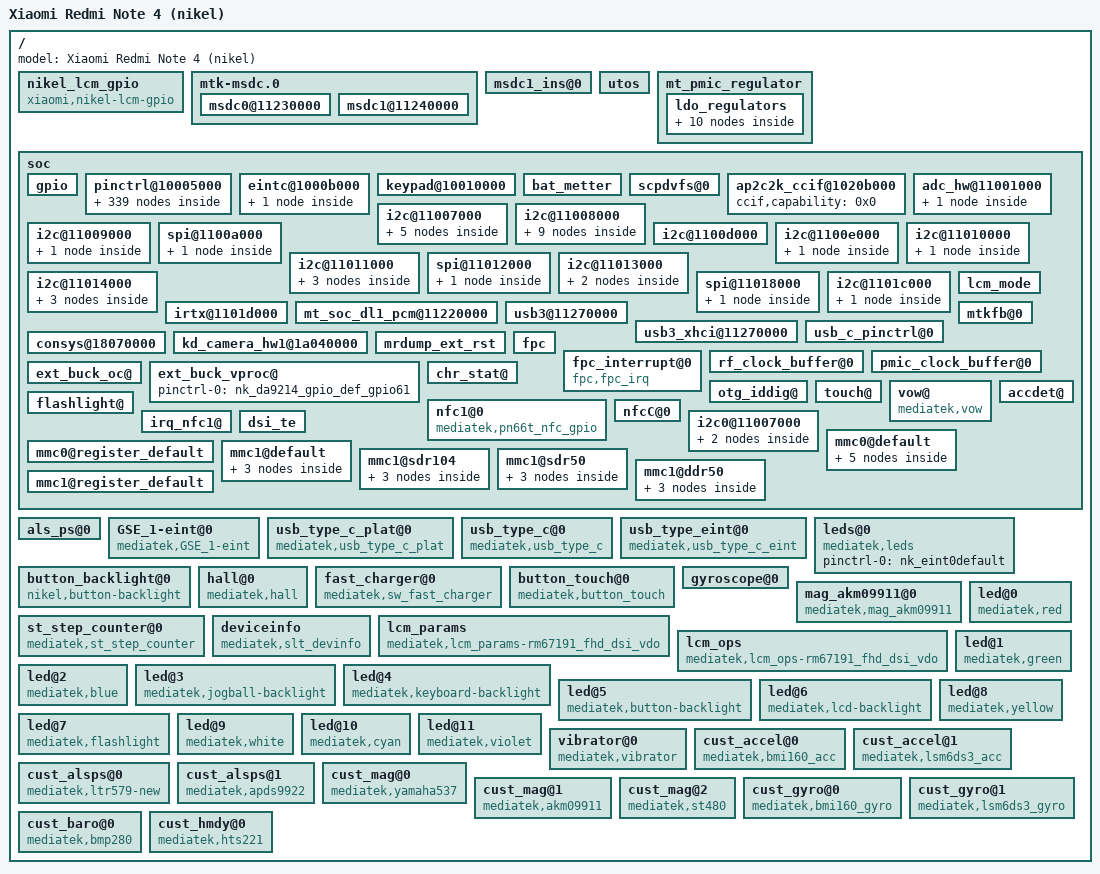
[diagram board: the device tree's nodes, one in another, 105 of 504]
/*
 * Redmi Note 4 (MTK, "nikel") - board device tree
 * Target: SHIFTPHONES/android_kernel_shift_mt6797 (shift-8.0-mtk, 3.18.60)
 * Built as CONFIG_BUILD_ARM64_APPENDED_DTB_IMAGE_NAMES="nikel" (nikel_defconfig),
 * one merged DTB appended to the kernel, no odmdtbo (nikel's LK has none).
 *
 * GENERATED DRAFT. Built by diffing nikel's stock DTB (Xiaomi kernel
 * 3.18.M2+, 2019-04-19, taken from a LineageOS 14.1 boot.img) against the
 * SoC tree inside SHIFT5ME.SOS.2.0.L.20230421's boot.img. Only what nikel's
 * board needs on top of SHIFT's mt6797.dtsi is here.
 *
 * Rules used:
 *  - Board data (pins, I2C/SPI devices, EINTs, touch, keypad, LEDs, sensors,
 *    camera power, LCM pins, battery tables) = nikel stock, verbatim.
 *  - SoC/kernel-version data (clock IDs, driver compatibles, I2C PM flags)
 *    = SHIFT, untouched.
 *  - Firmware-tied data (TEE interrupts, modem CCIF) = nikel, because nikel
 *    keeps its own TEE and modem images.
 *  - Phandles rewritten: SHIFT labels where they exist, otherwise generated
 *    "nk_*" labels on nikel's own pin-state nodes.
 *
 * Not yet compiled. First test: build with the kernel's dtc, then compare the
 * result against nikel's stock DTB with the same diff script.
 */

/dts-v1/;

/*
 * SHIFT's MT6797 SoC description - the same file SHIFT5me.dts includes when
 * CONFIG_MTK_DTBO_FEATURE is off, and the source of the base DTB this board
 * file was diffed against.
 */
#include "SHIFT5me_mt6797.dts"

/ {
	model = "Xiaomi Redmi Note 4 (nikel)";

	/*
	 * SHIFT5me_mt6797.dts declares early-mount entries here for system
	 * (non-A/B, with verity), vendor and optionally odm. nikel has no vendor
	 * or odm partition and mounts system from its normal fstab: without this
	 * deletion Android 8 init tries the early mounts and stops.
	 */
	/delete-node/ firmware;

	/*
	 * Panel pins for the nt35596_fhd_tianma_phantom driver, which drives
	 * reset, bias and backlight-enable itself (SHIFT's display driver only
	 * offers register-based reset and a combined bias switch).
	 * RST GPIO180, ENP GPIO87, ENN GPIO108, BL_EN GPIO50 - nikel stock states.
	 */
	nikel_lcm_gpio {
		compatible = "xiaomi,nikel-lcm-gpio";
		pinctrl-names = "rst0", "rst1", "enp0", "enp1", "enn0", "enn1", "bl0", "bl1";
		pinctrl-0 = <&nk_lcm_rst_out0_gpio>;
		pinctrl-1 = <&nk_lcm_rst_out1_gpio>;
		pinctrl-2 = <&nk_lcd_bias_enp_gpio_low>;
		pinctrl-3 = <&nk_lcd_bias_enp_gpio_high>;
		pinctrl-4 = <&nk_lcd_bias_enn_gpio_low>;
		pinctrl-5 = <&nk_lcd_bias_enn_gpio_high>;
		pinctrl-6 = <&nk_lcd_backlight_en_gpio_low>;
		pinctrl-7 = <&nk_lcd_backlight_en_gpio_high>;
		status = "okay";
	};
	mtk-msdc.0 {
		msdc0@11230000 {
			status = "okay";
			clk_src = [01];
			bus-width = <0x8>;
			max-frequency = <0xbebc200>;
			cap-mmc-highspeed;
			msdc-sys-suspend;
			mmc-ddr-1_8v;
			mmc-hs200-1_8v;
			mmc-hs400-1_8v;
			non-removable;
			pinctl = <0x3>;
			register_setting = <0x4>;
			host_function = [00];
			bootable;
		};
		msdc1@11240000 {
			status = "okay";
			clk_src = [02];
			bus-width = <0x4>;
			max-frequency = <0xbebc200>;
			msdc-sys-suspend;
			cap-sd-highspeed;
			sd-uhs-sdr12;
			sd-uhs-sdr25;
			sd-uhs-sdr50;
			sd-uhs-sdr104;
			pinctl = <0x5>;
			pinctl_sdr104 = <0x6>;
			pinctl_sdr50 = <0x7>;
			pinctl_ddr50 = <0x8>;
			register_setting = <0x9>;
			host_function = [01];
			cd_level = [00];
			cd-gpios = <&pio 0x43 0x0>;
		};
	};
	msdc1_ins@0 {
		interrupt-parent = <&eintc>;
		interrupts = <0x43 0x8>;
		debounce = <0x43 0x3e8>;
		status = "okay";
	};
	utos {
		interrupts = <0x0 0x126 0x1 0x0 0x127 0x1 0x0 0x128 0x1 0x0 0x12c 0x1
			    0x0 0x12d 0x1 0x0 0x12e 0x1 0x0 0x12f 0x1 0x0 0x131 0x1>;
	};
	mt_pmic_regulator {
		ldo_regulators {
			ldo_vcama {
				regulator-default-on = <0x1>;
				status = "okay";
			};
			ldo_vsim1 {
				regulator-default-on = <0x1>;
				status = "okay";
			};
			ldo_vsim2 {
				regulator-default-on = <0x1>;
				status = "okay";
			};
			ldo_vmch {
				regulator-boot-on;
			};
			ldo_vibr {
				regulator-default-on = <0x1>;
				status = "okay";
			};
			ldo_vcamd {
				regulator-default-on = <0x1>;
				status = "okay";
			};
			ldo_vcamio {
				regulator-default-on = <0x1>;
				status = "okay";
			};
			ldo_vgp3 {
				regulator-default-on = <0x1>;
				status = "okay";
			};
			ldo_vldo28 {
				regulator-default-on = <0x1>;
				status = "okay";
			};
			ldo_vmc {
				regulator-boot-on;
			};
		};
	};
	soc {
		gpio {
			GPIO_SIM1_HOT_PLUG = <0x70>;
			GPIO_SIM2_HOT_PLUG = <0x71>;
			GPIO_SIM1_SCLK = <0x7e>;
			GPIO_SIM1_SRST = <0x7f>;
			GPIO_SIM1_SIO = <0x80>;
			GPIO_SIM2_SCLK = <0x9b>;
			GPIO_SIM2_SRST = <0x9c>;
			GPIO_SIM2_SIO = <0x9d>;
		};
		pinctrl@10005000 {
			nk_default: default {
			};
			nk_bq_dsel_en_l: bq_dsel_en_l {
				pins_cmd_dat {
					pins = <0x8a00>;
					slew-rate = <0x1>;
					output-low;
				};
			};
			nk_bq_dsel_en_h: bq_dsel_en_h {
				pins_cmd_dat {
					pins = <0x8a00>;
					slew-rate = <0x1>;
					output-high;
				};
			};
			nk_alspspincfg: alspspincfg {
				pins_cmd_dat {
					pins = <0x5801>;
					slew-rate = <0x0>;
					bias-pull-up = <0x0>;
				};
			};
			nk_alspsdefaultcfg: alspsdefaultcfg {
			};
			nk_steppincfg: steppincfg {
				pins_cmd_dat {
					pins = <0x3e01>;
					slew-rate = <0x0>;
					bias-pull-up = <0x0>;
				};
			};
			nk_stepdefaultcfg: stepdefaultcfg {
			};
			nk_gyropincfg: gyropincfg {
				pins_cmd_dat {
					pins = <0x3f00>;
					slew-rate = <0x0>;
					bias-pull-down = <0x0>;
				};
			};
			nk_gyrodefaultcfg: gyrodefaultcfg {
			};
			nk_magpincfg: magpincfg {
				pins_cmd_dat {
					pins = <0x4000>;
					slew-rate = <0x1>;
					bias-disable;
					bias-pull-down = <0x0>;
					bias-pull-up = <0x0>;
					input-disable;
					input-schmitt-enable = <0x0>;
					output-high;
				};
			};
			nk_magdefaultcfg: magdefaultcfg {
				pins_cmd_dat {
					pins = <0x4000>;
					slew-rate = <0x1>;
					bias-disable;
					bias-pull-down = <0x0>;
					bias-pull-up = <0x0>;
					input-disable;
					input-schmitt-enable = <0x0>;
					output-low;
				};
			};
			nk_state_default: state_default {
			};
			nk_state_reset_high: state_reset_high {
				pins_cmd_dat {
					pins = <0x2b00>;
					slew-rate = <0x1>;
					output-high;
				};
			};
			nk_state_reset_low: state_reset_low {
				pins_cmd_dat {
					pins = <0x2b00>;
					slew-rate = <0x1>;
					output-low;
				};
			};
			nk_state_power_on: state_power_on {
				pins_cmd_dat {
					pins = <0x8b00>;
					slew-rate = <0x1>;
					output-high;
				};
			};
			nk_state_power_off: state_power_off {
				pins_cmd_dat {
					pins = <0x8b00>;
					slew-rate = <0x1>;
					output-low;
				};
			};
			nk_state_gf_irq: state_gf_irq {
				pins_cmd_dat {
					pins = <0x5601>;
					slew-rate = <0x0>;
					bias-disable;
				};
			};
			nk_state_tas_mod_switch1_high: state_tas_mod_switch1_high {
				pins_cmd_dat {
					pins = <0xc900>;
					slew-rate = <0x1>;
					bias-disable;
					output-high;
				};
			};
			nk_state_tas_mod_switch1_low: state_tas_mod_switch1_low {
				pins_cmd_dat {
					pins = <0xc900>;
					slew-rate = <0x1>;
					bias-disable;
					output-low;
				};
			};
			nk_state_tas_mod_switch2_high: state_tas_mod_switch2_high {
				pins_cmd_dat {
					pins = <0xcb00>;
					slew-rate = <0x1>;
					bias-disable;
					output-high;
				};
			};
			nk_state_tas_mod_switch2_low: state_tas_mod_switch2_low {
				pins_cmd_dat {
					pins = <0xcb00>;
					slew-rate = <0x1>;
					bias-disable;
					output-low;
				};
			};
			nk_state_tas_mod_switch1_bpi_mode: state_tas_mod_switch1_bpi_mode {
				pins_cmd_dat {
					pins = <0xc901>;
					slew-rate = <0x1>;
					bias-disable;
				};
			};
			nk_state_tas_mod_switch2_bpi_mode: state_tas_mod_switch2_bpi_mode {
				pins_cmd_dat {
					pins = <0xcb01>;
					slew-rate = <0x1>;
					bias-disable;
				};
			};
			nk_st1_eint_init: st1_eint_init {
				pins_cmd_dat {
					pins = <0x5d01>;
					slew-rate = <0x0>;
					bias-pull-down = <0x0>;
				};
			};
			nk_st1_se_eint_init: st1_se_eint_init {
				pins_cmd_dat {
					pins = <0x5901>;
					slew-rate = <0x0>;
					bias-pull-up = <0x0>;
				};
			};
			nk_st1_ven_high: st1_ven_high {
				pins_cmd_dat {
					pins = <0x3b00>;
					slew-rate = <0x1>;
					output-high;
				};
			};
			nk_st1_ven_low: st1_ven_low {
				pins_cmd_dat {
					pins = <0x3b00>;
					slew-rate = <0x1>;
					output-low;
				};
			};
			nk_st1_dl_req_high: st1_dl_req_high {
				pins_cmd_dat {
					pins = <0x2700>;
					slew-rate = <0x1>;
					output-high;
				};
			};
			nk_st1_dl_req_low: st1_dl_req_low {
				pins_cmd_dat {
					pins = <0x2700>;
					slew-rate = <0x1>;
					output-low;
				};
			};
			nk_st1_se_en_high: st1_se_en_high {
				pins_cmd_dat {
					pins = <0x2800>;
					slew-rate = <0x1>;
					output-high;
				};
			};
			nk_st1_se_en_low: st1_se_en_low {
				pins_cmd_dat {
					pins = <0x2800>;
					slew-rate = <0x1>;
					output-low;
				};
			};
			nk_st1_pvdd_en_high: st1_pvdd_en_high {
				pins_cmd_dat {
					pins = <0x2900>;
					slew-rate = <0x1>;
					output-high;
				};
			};
			nk_st1_pvdd_en_low: st1_pvdd_en_low {
				pins_cmd_dat {
					pins = <0x2900>;
					slew-rate = <0x1>;
					output-low;
				};
			};
			nk_st1_se_rst_high: st1_se_rst_high {
				pins_cmd_dat {
					pins = <0x2a00>;
					slew-rate = <0x1>;
					output-high;
				};
			};
			nk_st1_se_rst_low: st1_se_rst_low {
				pins_cmd_dat {
					pins = <0x2a00>;
					slew-rate = <0x1>;
					output-low;
				};
			};
			nk_state_ven_high: state_ven_high {
				pins_cmd_dat {
					pins = <0x3c00>;
					slew-rate = <0x1>;
					output-high;
				};
			};
			nk_state_ven_low: state_ven_low {
				pins_cmd_dat {
					pins = <0x3c00>;
					slew-rate = <0x1>;
					output-low;
				};
			};
			nk_state_rst_high: state_rst_high {
				pins_cmd_dat {
					pins = <0x3b00>;
					slew-rate = <0x1>;
					output-high;
				};
			};
			nk_state_rst_low: state_rst_low {
				pins_cmd_dat {
					pins = <0x3b00>;
					slew-rate = <0x1>;
					output-low;
				};
			};
			nk_state_eint_high: state_eint_high {
				pins_cmd_dat {
					pins = <0x3900>;
					slew-rate = <0x1>;
					output-high;
				};
			};
			nk_state_eint_low: state_eint_low {
				pins_cmd_dat {
					pins = <0x3900>;
					slew-rate = <0x1>;
					output-low;
				};
			};
			nk_state_irq_init: state_irq_init {
				pins_cmd_dat {
					pins = <0x1c00>;
					slew-rate = <0x0>;
					bias-pull-down = <0x0>;
				};
			};
			nk_state_osc_init: state_osc_init {
				pins_cmd_dat {
					pins = <0x6400>;
					slew-rate = <0x1>;
					bias-pull-down = <0x0>;
				};
			};
			nk_state_cs_low: state_cs_low {
				pins_cmd_dat {
					pins = <0xf500>;
					slew-rate = <0x1>;
					output-low;
					input-disable;
				};
			};
			nk_state_mo_low: state_mo_low {
				pins_cmd_dat {
					pins = <0xf400>;
					slew-rate = <0x1>;
					output-low;
					input-disable;
				};
			};
			nk_state_mi_low: state_mi_low {
				pins_cmd_dat {
					pins = <0xf300>;
					slew-rate = <0x1>;
					output-low;
					input-disable;
				};
			};
			nk_state_sck_low: state_sck_low {
				pins_cmd_dat {
					pins = <0xf200>;
					slew-rate = <0x1>;
					output-low;
					input-disable;
				};
			};
			nk_eint0default: eint0default {
			};
			nk_eint_0: eint@0 {
				pins_cmd_dat {
					pins = <0x5501>;
					slew-rate = <0x0>;
					bias-disable;
				};
			};
			nk_eintoutput0: eintoutput0 {
				pins_cmd_dat {
					pins = <0x5500>;
					slew-rate = <0x1>;
					output-low;
				};
			};
			nk_eintoutput1: eintoutput1 {
				pins_cmd_dat {
					pins = <0x5500>;
					slew-rate = <0x1>;
					output-high;
				};
			};
			nk_rstoutput0: rstoutput0 {
				pins_cmd_dat {
					pins = <0x4400>;
					slew-rate = <0x1>;
					output-low;
				};
			};
			nk_rstoutput1: rstoutput1 {
				pins_cmd_dat {
					pins = <0x4400>;
					slew-rate = <0x1>;
					output-high;
				};
			};
			nk_regulator_en_output0: regulator_en_output0 {
				pins_cmd_dat {
					pins = <0x3a00>;
					slew-rate = <0x1>;
					output-low;
				};
			};
			nk_regulator_en_output1: regulator_en_output1 {
				pins_cmd_dat {
					pins = <0x3a00>;
					slew-rate = <0x1>;
					output-high;
				};
			};
			nk_accdetdefault: accdetdefault {
			};
			nk_accdeteint_0: accdeteint@0 {
				pins_cmd_dat {
					pins = <0x5c01>;
					slew-rate = <0x0>;
					bias-disable;
				};
			};
			nk_aud_clk_mosi_off: aud_clk_mosi_off {
				pins_cmd0_dat {
					pins = <0x9200>;
				};
			};
			nk_aud_clk_mosi_on: aud_clk_mosi_on {
				pins_cmd0_dat {
					pins = <0x9201>;
				};
			};
			nk_aud_pins_smartpa_mode0: aud_pins_smartpa_mode0 {
				pins_cmd0_dat {
					pins = <0x4500>;
				};
				pins_cmd1_dat {
					pins = <0x4600>;
				};
				pins_cmd2_dat {
					pins = <0x4800>;
				};
				pins_cmd3_dat {
					pins = <0x4900>;
				};
			};
			nk_aud_pins_smartpa_mode1: aud_pins_smartpa_mode1 {
				pins_cmd0_dat {
					pins = <0x4501>;
				};
				pins_cmd1_dat {
					pins = <0x4601>;
				};
				pins_cmd2_dat {
					pins = <0x4802>;
				};
				pins_cmd3_dat {
					pins = <0x4902>;
				};
			};
			nk_aud_pins_smartpa_mode3: aud_pins_smartpa_mode3 {
				pins_cmd0_dat {
					pins = <0x4503>;
				};
				pins_cmd1_dat {
					pins = <0x4603>;
				};
				pins_cmd2_dat {
					pins = <0x4804>;
				};
				pins_cmd3_dat {
					pins = <0x4904>;
				};
			};
			nk_aud_pins_tdm_mode0: aud_pins_tdm_mode0 {
				pins_cmd0_dat {
					pins = <0x7100>;
				};
				pins_cmd1_dat {
					pins = <0x8800>;
				};
				pins_cmd2_dat {
					pins = <0x8a00>;
				};
			};
			nk_aud_pins_tdm_mode1: aud_pins_tdm_mode1 {
				pins_cmd0_dat {
					pins = <0x8701>;
				};
				pins_cmd1_dat {
					pins = <0x8801>;
				};
				pins_cmd2_dat {
					pins = <0x8a01>;
				};
			};
			nk_audhpdepophigh: audhpdepophigh {
				pins_cmd_dat {
					pins = <0x6f00>;
					slew-rate = <0x1>;
					output-high;
				};
			};
			nk_audhpdepoplow: audhpdepoplow {
				pins_cmd_dat {
					pins = <0x6f00>;
					slew-rate = <0x1>;
					output-low;
				};
			};
			nk_aud_dat_miso_off: aud_dat_miso_off {
				pins_cmd1_dat {
					pins = <0x9300>;
				};
			};
			nk_aud_dat_miso_on: aud_dat_miso_on {
				pins_cmd1_dat {
					pins = <0x9301>;
				};
			};
			nk_aud_dat_mosi_off: aud_dat_mosi_off {
				pins_cmd2_dat {
					pins = <0x9400>;
				};
			};
			nk_aud_dat_mosi_on: aud_dat_mosi_on {
				pins_cmd2_dat {
					pins = <0x9401>;
				};
			};
			nk_vow_dat_miso_off: vow_dat_miso_off {
				pins_cmd1_dat {
					pins = <0x9300>;
				};
			};
			nk_vow_dat_miso_on: vow_dat_miso_on {
				pins_cmd1_dat {
					pins = <0x9303>;
				};
			};
			nk_vow_clk_miso_off: vow_clk_miso_off {
				pins_cmd3_dat {
					pins = <0x9500>;
				};
			};
			nk_vow_clk_miso_on: vow_clk_miso_on {
				pins_cmd3_dat {
					pins = <0x9501>;
				};
			};
			nk_anc_dat_mosi_off: anc_dat_mosi_off {
				pins_cmd4_dat {
					pins = <0x9600>;
				};
			};
			nk_anc_dat_mosi_on: anc_dat_mosi_on {
				pins_cmd4_dat {
					pins = <0x9601>;
				};
			};
			nk_aud_extamp_high: aud_extamp_high {
				pins_cmd_dat {
					pins = <0x4700>;
					slew-rate = <0x1>;
					output-high;
				};
			};
			nk_aud_extamp_low: aud_extamp_low {
				pins_cmd_dat {
					pins = <0x4700>;
					slew-rate = <0x1>;
					output-low;
				};
			};
			nk_mode_te_gpio: mode_te_gpio {
				pins_cmd_dat {
					pins = <0xb301>;
				};
			};
			nk_mode_te_te: mode_te_te {
				pins_cmd_dat {
					pins = <0xb301>;
				};
			};
			nk_lcm_rst_out0_gpio: lcm_rst_out0_gpio {
				pins_cmd_dat {
					pins = <0xb400>;
					slew-rate = <0x1>;
					output-low;
				};
			};
			nk_lcm_rst_out1_gpio: lcm_rst_out1_gpio {
				pins_cmd_dat {
					pins = <0xb400>;
					slew-rate = <0x1>;
					output-high;
				};
			};
			nk_lcd_bias_enp_gpio_high: lcd_bias_enp_gpio_high {
				pins_cmd_dat {
					pins = <0x5700>;
					slew-rate = <0x1>;
					output-high;
				};
			};
			nk_lcd_bias_enp_gpio_low: lcd_bias_enp_gpio_low {
				pins_cmd_dat {
					pins = <0x5700>;
					slew-rate = <0x1>;
					output-low;
				};
			};
			nk_lcd_pwr_en_gpio_high: lcd_pwr_en_gpio_high {
				pins_cmd_dat {
					pins = <0x2d00>;
					slew-rate = <0x1>;
					output-high;
				};
			};
			nk_lcd_pwr_en_gpio_low: lcd_pwr_en_gpio_low {
				pins_cmd_dat {
					pins = <0x2d00>;
					slew-rate = <0x1>;
					output-low;
				};
			};
			nk_lcd_bias_enn_gpio_high: lcd_bias_enn_gpio_high {
				pins_cmd_dat {
					pins = <0x6c00>;
					slew-rate = <0x1>;
					output-high;
				};
			};
			nk_lcd_bias_enn_gpio_low: lcd_bias_enn_gpio_low {
				pins_cmd_dat {
					pins = <0x6c00>;
					slew-rate = <0x1>;
					output-low;
				};
			};
			nk_lcd_backlight_en_gpio_high: lcd_backlight_en_gpio_high {
				pins_cmd_dat {
					pins = <0x3200>;
					slew-rate = <0x1>;
					output-high;
				};
			};
			nk_lcd_backlight_en_gpio_low: lcd_backlight_en_gpio_low {
				pins_cmd_dat {
					pins = <0x3200>;
					slew-rate = <0x1>;
					output-low;
				};
			};
			nk_cam0_0: cam0@0 {
				pins_cmd_dat {
					pins = <0x2000>;
					slew-rate = <0x1>;
					output-low;
				};
			};
			nk_cam0_1: cam0@1 {
				pins_cmd_dat {
					pins = <0x2000>;
					slew-rate = <0x1>;
					output-high;
				};
			};
			nk_cam0_2: cam0@2 {
				pins_cmd_dat {
					pins = <0x1c00>;
					slew-rate = <0x1>;
					output-low;
				};
			};
			nk_cam0_3: cam0@3 {
				pins_cmd_dat {
					pins = <0x1c00>;
					slew-rate = <0x1>;
					output-high;
				};
			};
			nk_cam1_0: cam1@0 {
				pins_cmd_dat {
					pins = <0x2100>;
					slew-rate = <0x1>;
					output-low;
				};
			};
			nk_cam1_1: cam1@1 {
				pins_cmd_dat {
					pins = <0x2100>;
					slew-rate = <0x1>;
					output-high;
				};
			};
			nk_cam1_2: cam1@2 {
				pins_cmd_dat {
					pins = <0x1d00>;
					slew-rate = <0x1>;
					output-low;
				};
			};
			nk_cam1_3: cam1@3 {
				pins_cmd_dat {
					pins = <0x1d00>;
					slew-rate = <0x1>;
					output-high;
				};
			};
			nk_cam2_0: cam2@0 {
				pins_cmd_dat {
					pins = <0x2300>;
					slew-rate = <0x1>;
					output-low;
				};
			};
			nk_cam2_1: cam2@1 {
				pins_cmd_dat {
					pins = <0x2300>;
					slew-rate = <0x1>;
					output-high;
				};
			};
			nk_cam2_2: cam2@2 {
				pins_cmd_dat {
					pins = <0x2200>;
					slew-rate = <0x1>;
					output-low;
				};
			};
			nk_cam2_3: cam2@3 {
				pins_cmd_dat {
					pins = <0x2200>;
					slew-rate = <0x1>;
					output-high;
				};
			};
			nk_cam0_vcama0: cam0@vcama0 {
				pins_cmd_dat {
					pins = <0xfd00>;
					slew-rate = <0x1>;
					output-low;
				};
			};
			nk_cam1_vcama1: cam1@vcama1 {
				pins_cmd_dat {
					pins = <0xfd00>;
					slew-rate = <0x1>;
					output-high;
				};
			};
			nk_cam0_vcamd0: cam0@vcamd0 {
				pins_cmd_dat {
					pins = <0x2900>;
					slew-rate = <0x1>;
					output-low;
				};
			};
			nk_cam1_vcamd1: cam1@vcamd1 {
				pins_cmd_dat {
					pins = <0x2900>;
					slew-rate = <0x1>;
					output-high;
				};
			};
			nk_cam2_vcama0: cam2@vcama0 {
				pins_cmd_dat {
					pins = <0x3000>;
					slew-rate = <0x1>;
					output-low;
				};
			};
			nk_cam2_vcama1: cam2@vcama1 {
				pins_cmd_dat {
					pins = <0x3000>;
					slew-rate = <0x1>;
					output-high;
				};
			};
			nk_camdefault: camdefault {
			};
			nk_gpslna_0: gpslna@0 {
				pins_cmd_dat {
					pins = <0x8d00>;
					slew-rate = <0x0>;
					bias-disable;
					output-low;
				};
			};
			nk_gpslna_1: gpslna@1 {
				pins_cmd_dat {
					pins = <0x8d00>;
					slew-rate = <0x1>;
					output-high;
				};
			};
			nk_gpslna_2: gpslna@2 {
				pins_cmd_dat {
					pins = <0x8d00>;
					slew-rate = <0x1>;
					output-low;
				};
			};
			nk_usb_default: usb_default {
			};
			nk_gpio197_redriver_c1_init: gpio197_redriver_c1_init {
				pins_cmd_dat {
					pins = <0xc500>;
					slew-rate = <0x1>;
					output-low;
				};
			};
			nk_gpio197_redriver_c1_low: gpio197_redriver_c1_low {
				pins_cmd_dat {
					pins = <0xc500>;
					slew-rate = <0x1>;
					output-low;
				};
			};
			nk_gpio197_redriver_c1_highz: gpio197_redriver_c1_highz {
				pins_cmd_dat {
					pins = <0xc500>;
					slew-rate = <0x0>;
					bias-disable;
				};
			};
			nk_gpio197_redriver_c1_high: gpio197_redriver_c1_high {
				pins_cmd_dat {
					pins = <0xc500>;
					slew-rate = <0x1>;
					output-high;
				};
			};
			nk_gpio196_redriver_c2_init: gpio196_redriver_c2_init {
				pins_cmd_dat {
					pins = <0xc400>;
					slew-rate = <0x1>;
					output-low;
				};
			};
			nk_gpio196_redriver_c2_low: gpio196_redriver_c2_low {
				pins_cmd_dat {
					pins = <0xc400>;
					slew-rate = <0x1>;
					output-low;
				};
			};
			nk_gpio196_redriver_c2_highz: gpio196_redriver_c2_highz {
				pins_cmd_dat {
					pins = <0xc400>;
					slew-rate = <0x0>;
					bias-disable;
				};
			};
			nk_gpio196_redriver_c2_high: gpio196_redriver_c2_high {
				pins_cmd_dat {
					pins = <0xc400>;
					slew-rate = <0x1>;
					output-high;
				};
			};
			nk_gpio251_fusb340_noe_init: gpio251_fusb340_noe_init {
				pins_cmd_dat {
					pins = <0xfb00>;
					slew-rate = <0x1>;
					output-high;
				};
			};
			nk_gpio251_fusb340_noe_low: gpio251_fusb340_noe_low {
				pins_cmd_dat {
					pins = <0xfb00>;
					slew-rate = <0x1>;
					output-low;
				};
			};
			nk_gpio251_fusb340_noe_high: gpio251_fusb340_noe_high {
				pins_cmd_dat {
					pins = <0xfb00>;
					slew-rate = <0x1>;
					output-high;
				};
			};
			nk_gpio252_fusb340_sel_init: gpio252_fusb340_sel_init {
				pins_cmd_dat {
					pins = <0xfd00>;
					slew-rate = <0x1>;
					output-low;
				};
			};
			nk_gpio252_fusb340_sel_low: gpio252_fusb340_sel_low {
				pins_cmd_dat {
					pins = <0xfd00>;
					slew-rate = <0x1>;
					output-low;
				};
			};
			nk_gpio252_fusb340_sel_high: gpio252_fusb340_sel_high {
				pins_cmd_dat {
					pins = <0xfd00>;
					slew-rate = <0x1>;
					output-high;
				};
			};
			nk_hwen_high: hwen_high {
				pins_cmd_dat {
					pins = <0x8c00>;
					slew-rate = <0x1>;
					output-high;
				};
			};
			nk_hwen_low: hwen_low {
				pins_cmd_dat {
					pins = <0x8c00>;
					slew-rate = <0x1>;
					output-low;
				};
			};
			nk_enm_high: enm_high {
				pins_cmd_dat {
					pins = <0xff00>;
					slew-rate = <0x1>;
					output-high;
				};
			};
			nk_enm_low: enm_low {
				pins_cmd_dat {
					pins = <0xff00>;
					slew-rate = <0x1>;
					output-low;
				};
			};
			nk_enf_high: enf_high {
				pins_cmd_dat {
					pins = <0x8900>;
					slew-rate = <0x1>;
					output-high;
				};
			};
			nk_enf_low: enf_low {
				pins_cmd_dat {
					pins = <0x8900>;
					slew-rate = <0x1>;
					output-low;
				};
			};
			nk_irtx_gpio_led_def_gpio135: irtx_gpio_led_def@gpio135 {
				pins_cmd_dat {
					pins = <0x8700>;
					slew-rate = <0x0>;
					bias-pull-down = <0x0>;
					input-schmitt-enable = <0x0>;
				};
			};
			nk_irtx_gpio_led_set_gpio135: irtx_gpio_led_set@gpio135 {
				pins_cmd_dat {
					pins = <0x8705>;
					slew-rate = <0x1>;
					bias-disable;
					bias-pull-down = <0x0>;
					output-low;
					input-schmitt-enable = <0x0>;
				};
			};
			nk_iddig_default: iddig_default {
			};
			nk_iddig_init: iddig_init {
				pins_cmd_dat {
					pins = <0xb501>;
					slew-rate = <0x0>;
					bias-pull-up = <0x0>;
				};
			};
			nk_drvvbus_default: drvvbus_default {
			};
			nk_drvvbus_low: drvvbus_low {
				pins_cmd_dat {
					pins = <0x5e01>;
					slew-rate = <0x1>;
					output-low;
				};
			};
			nk_drvvbus_high: drvvbus_high {
				pins_cmd_dat {
					pins = <0x5e01>;
					slew-rate = <0x1>;
					output-high;
				};
			};
			nk_lcm_mode_default: lcm_mode_default {
				pins_cmd_dat {
					pins = <0x4100>;
				};
			};
			nk_lcm_mode_0: lcm_mode@0 {
				pins_cmd_dat {
					pins = <0x4100>;
				};
			};
			nk_lcm_mode_1: lcm_mode@1 {
				pins_cmd_dat {
					pins = <0x4101>;
				};
			};
			nk_lcm_mode_2: lcm_mode@2 {
				pins_cmd_dat {
					pins = <0x4102>;
				};
			};
			nk_lcm_mode_3: lcm_mode@3 {
				pins_cmd_dat {
					pins = <0x4103>;
				};
			};
			nk_lcm_mode_4: lcm_mode@4 {
				pins_cmd_dat {
					pins = <0x4104>;
				};
			};
			nk_lcm_mode_5: lcm_mode@5 {
				pins_cmd_dat {
					pins = <0x4105>;
				};
			};
			nk_lcm_mode_7: lcm_mode@7 {
				pins_cmd_dat {
					pins = <0x4107>;
				};
			};
			nk_spi1_gpio_default: spi1_gpio_default {
			};
			nk_spi1_cs_set_gpio237: spi1_cs_set@gpio237 {
				pins_cmd_dat {
					pins = <0xed01>;
					input-enable;
				};
			};
			nk_spi1_cs_clear_gpio237: spi1_cs_clear@gpio237 {
				pins_cmd_dat {
					pins = <0xed00>;
					slew-rate = <0x0>;
					input-disable;
					bias-disable;
					input-schmitt-enable;
				};
			};
			nk_spi1_clk_set_gpio234: spi1_clk_set@gpio234 {
				pins_cmd_dat {
					pins = <0xea01>;
					input-enable;
				};
			};
			nk_spi1_clk_clear_gpio234: spi1_clk_clear@gpio234 {
				pins_cmd_dat {
					pins = <0xea00>;
					slew-rate = <0x0>;
					input-disable;
					bias-disable;
					input-schmitt-enable;
				};
			};
			nk_spi1_miso_set_gpio235: spi1_miso_set@gpio235 {
				pins_cmd_dat {
					pins = <0xeb01>;
					input-enable;
				};
			};
			nk_spi1_miso_clear_gpio235: spi1_miso_clear@gpio235 {
				pins_cmd_dat {
					pins = <0xeb00>;
					slew-rate = <0x0>;
					input-disable;
					bias-disable;
					input-schmitt-enable;
				};
			};
			nk_spi1_mosi_set_gpio236: spi1_mosi_set@gpio236 {
				pins_cmd_dat {
					pins = <0xec01>;
					input-enable;
				};
			};
			nk_spi1_mosi_clear_gpio236: spi1_mosi_clear@gpio236 {
				pins_cmd_dat {
					pins = <0xec00>;
					slew-rate = <0x0>;
					input-disable;
					bias-disable;
					input-schmitt-enable;
				};
			};
			nk_scp_gpio_off: scp_gpio_off {
				pins_cmd_dat {
					pins = <0x9200>;
				};
			};
			nk_scp_gpio_on: scp_gpio_on {
				pins_cmd_dat {
					pins = <0x9201>;
				};
			};
			nk_da9214_gpio_def_gpio61: da9214_gpio_def@gpio61 {
				pins_cmd_dat {
					pins = <0x3d00>;
					slew-rate = <0x1>;
					bias-disable;
					output-low;
					input-schmitt-enable = <0x0>;
				};
			};
			nk_hall_eint0_default: hall_eint0_default {
			};
			nk_hall_eint_0: hall_eint@0 {
				pins_cmd_dat {
					pins = <0x5b01>;
					slew-rate = <0x0>;
					bias-disable;
				};
			};
			nk_hall_eint_output0: hall_eint_output0 {
				pins_cmd_dat {
					pins = <0x5b00>;
					slew-rate = <0x1>;
					output-low;
				};
			};
			nk_hall_eint_output1: hall_eint_output1 {
				pins_cmd_dat {
					pins = <0x5b00>;
					slew-rate = <0x1>;
					output-high;
				};
			};
			nk_hall_select_output0: hall_select_output0 {
				pins_cmd_dat {
					pins = <0x5a00>;
					slew-rate = <0x1>;
					output-low;
				};
			};
			nk_hall_select_output1: hall_select_output1 {
				pins_cmd_dat {
					pins = <0x5a00>;
					slew-rate = <0x1>;
					output-high;
				};
			};
			nk_button_backlight0: button_backlight0 {
				pins_cmd_dat {
					pins = <0xfc00>;
					slew-rate = <0x1>;
					output-low;
				};
			};
			nk_button_backlight1: button_backlight1 {
				pins_cmd_dat {
					pins = <0xfc00>;
					slew-rate = <0x1>;
					output-high;
				};
			};
			nk_typec_default1: typec_default1 {
			};
			nk_typec_eint_int1: typec_eint_int1 {
				pins_cmd_dat {
					pins = <0x5901>;
					slew-rate = <0x0>;
					bias-pull-up = <0x0>;
				};
			};
		};
		eintc@1000b000 {
			mediatek,mapping_table_entry = <0xac>;
			mediatek,mapping_table = <0x3d 0x0 0x3e 0x1 0x3f 0x2 0x40 0x3 0x41 0x4 0x42 0x5
				    0x43 0x6 0x44 0x7 0x55 0x8 0x56 0x9 0x57 0xa 0x58 0xb
				    0x59 0xc 0x5a 0xd 0x5b 0xe 0x5c 0xf 0x5d 0x10 0x1c 0x11
				    0x1d 0x12 0x1f 0x13 0x20 0x14 0x21 0x15 0x22 0x16 0x23 0x17
				    0x24 0x18 0x25 0x19 0x26 0x1a 0x27 0x1b 0x28 0x1c 0x29 0x1d
				    0x2a 0x1e 0x2b 0x1f 0x2c 0x20 0x2d 0x21 0x2e 0x22 0x2f 0x23
				    0x30 0x24 0x31 0x25 0x32 0x26 0x33 0x27 0x34 0x28 0x35 0x29
				    0x36 0x2a 0x37 0x2b 0x38 0x2c 0x39 0x2d 0x3a 0x2e 0x3b 0x2f
				    0x3c 0x30 0x45 0x31 0x46 0x32 0x47 0x33 0x48 0x34 0x49 0x35
				    0x4a 0x36 0x4b 0x37 0x4c 0x38 0x4d 0x39 0x4e 0x3a 0x4f 0x3b
				    0x50 0x3c 0x51 0x3d 0x52 0x3e 0x53 0x3f 0x54 0x40 0x5e 0x41
				    0x5f 0x42 0x60 0x43 0x61 0x44 0x62 0x45 0x6a 0x49 0x6b 0x4a
				    0x6c 0x4b 0x6d 0x4c 0x6e 0x4d 0x6f 0x4e 0x70 0x4f 0x71 0x50
				    0x7e 0x51 0x7f 0x52 0x80 0x53 0x81 0x54 0x82 0x55 0x83 0x56
				    0x84 0x57 0x85 0x58 0x86 0x59 0x87 0x5a 0x88 0x5b 0x89 0x5c
				    0x8a 0x5d 0x8b 0x5e 0x8c 0x5f 0x8d 0x60 0x97 0x61 0x98 0x62
				    0x99 0x63 0x9a 0x64 0x9b 0x65 0x9c 0x66 0x9d 0x67 0xb3 0x68
				    0xb4 0x69 0xb5 0x6a 0xb7 0x6b 0xb8 0x6c 0xb9 0x6d 0xba 0x6e
				    0xbb 0x6f 0xbc 0x70 0xbd 0x71 0xbe 0x72 0xbf 0x73 0xc0 0x74
				    0xc1 0x75 0xc2 0x76 0xc3 0x77 0xc4 0x78 0xc5 0x79 0xc6 0x7a
				    0xc7 0x7b 0xc8 0x7c 0xc9 0x7d 0xca 0x7e 0xcb 0x7f 0xcc 0x80
				    0xcd 0x81 0xce 0x82 0xcf 0x83 0xd0 0x84 0xd1 0x85 0xd2 0x86
				    0xd3 0x87 0xd4 0x88 0xd5 0x89 0xd6 0x8a 0xd7 0x8b 0xd8 0x8c
				    0xd9 0x8d 0xda 0x8e 0xdb 0x8f 0xe8 0x90 0xe9 0x91 0xea 0x92
				    0xeb 0x93 0xec 0x94 0xed 0x95 0xee 0x96 0xef 0x97 0xf0 0x98
				    0xf1 0x99 0xf2 0x9a 0xf3 0x9b 0xf4 0x9c 0xf5 0x9d 0xf6 0x9e
				    0xf7 0x9f 0xf8 0xa0 0xf9 0xa1 0xfa 0xa2 0xfb 0xa3 0xfc 0xa4
				    0xfd 0xa5 0xfe 0xa6 0xff 0xa7 0x100 0xa8 0x101 0xa9 0x102 0xaa
				    0x103 0xab 0x104 0xac 0x105 0xad 0x106 0xb0>;
			mediatek,builtin_entry = <0x4>;
			mediatek,builtin_mapping = <0x3d 0x2 0xba 0x5d 0x2 0xba 0x6b 0x2 0xba 0xb5 0x1 0xba>;
			MD1_SIM1_HOT_PLUG_EINT@0 {
				compatible = "mediatek,MD1_SIM1_HOT_PLUG_EINT-eint";
				interrupts = <0x0 0x4>;
				debounce = <0x0 0x186a0>;
				dedicated = <0x0 0x0>;
				src_pin = <0x0 0x1>;
				sockettype = <0x0 0x0>;
				status = "okay";
			};
		};
		keypad@10010000 {
			mediatek,kpd-key-debounce = <0x400>;
			mediatek,kpd-sw-pwrkey = <0x74>;
			mediatek,kpd-hw-pwrkey = <0x8>;
			mediatek,kpd-sw-rstkey = <0x73>;
			mediatek,kpd-hw-rstkey = <0x11>;
			mediatek,kpd-use-extend-type = <0x0>;
			mediatek,kpd-hw-map-num = <0x48>;
			mediatek,kpd-hw-init-map = <0x72 0x0 0x0 0x0 0x0 0x0 0x0 0x0 0x0 0x0 0x0 0x0
				    0x0 0x0 0x0 0x0 0x0 0x0 0x0 0x0 0x0 0x0 0x0 0x0
				    0x0 0x0 0x0 0x0 0x0 0x0 0x0 0x0 0x0 0x0 0x0 0x0
				    0x0 0x0 0x0 0x0 0x0 0x0 0x0 0x0 0x0 0x0 0x0 0x0
				    0x0 0x0 0x0 0x0 0x0 0x0 0x0 0x0 0x0 0x0 0x0 0x0
				    0x0 0x0 0x0 0x0 0x0 0x0 0x0 0x0 0x0 0x0 0x0 0x0>;
			mediatek,kpd-pwrkey-eint-gpio = <0x0>;
			mediatek,kpd-pwkey-gpio-din = <0x0>;
			mediatek,kpd-hw-dl-key0 = <0x11>;
			mediatek,kpd-hw-dl-key1 = <0x0>;
			mediatek,kpd-hw-dl-key2 = <0x8>;
			mediatek,kpd-hw-recovery-key = <0x11>;
			mediatek,kpd-hw-factory-key = <0x0>;
			status = "okay";
		};
		bat_metter {
			/delete-property/ ac_charger_input_current;
			/delete-property/ mtk_pump_express_plus_support;
			/delete-property/ ta_start_battery_soc;
			/delete-property/ ta_stop_battery_soc;
			/delete-property/ ta_ac_12v_input_current;
			/delete-property/ ta_ac_9v_input_current;
			/delete-property/ ta_ac_7v_input_current;
			/delete-property/ ta_ac_charging_current;
			/delete-property/ ta_9v_support;
			/delete-property/ ta_12v_support;
			charging_full_current = <0x104>;
			ac_charger_current = <0x13880>;
			bat_low_temp_protect_enable = <0x0>;
			/*
			 * nikel: stock DT says 0, but the stock kernel never reads this property
			 * (compile-time HIGH_BATTERY_VOLTAGE_SUPPORT) and charges the 4.4 V cell to
			 * 4.37 V "Full". SHIFT's battery_common.c does read it, so 1 here reproduces
			 * stock: framework requests 4.34 V, BQ24296 driver maps it to 4.400 V (0x38).
			 */
			high_battery_voltage_support = <0x1>;
			/*
			 * Battery thermistor (NTC). The stock DT carries MediaTek's generic
			 * 10k NTC / 24k pull-up to 1.8 V, but the stock KERNEL uses compiled-in
			 * values: 68k NTC table (found in the stock Image) with a 100k pull-up
			 * to 2.8 V. Proof from stock sysfs: TEMPBATTVOLTAGE=943 mV ->
			 * 100000*943/(2800-943) = 50780 ohm = stock's TEMPERATURER -> 31 C.
			 * With the generic values our kernel read about -4 C and JEITA
			 * blocked charging.
			 */
			rbat_pull_up_r = <100000>;
			rbat_pull_up_volt = <2800>;
			/* negative temperatures as two's complement: 0xffffffec = -20 ... */
			batt_temperature_table_num = <17>;
			batt_temperature_table = <
				0xffffffec 667700  0xfffffff1 502600  0xfffffff6 381700  0xfffffffb 292300
				0 225400  5 175100  10 136900  15 107800  20 85350
				25 68000  30 54500  35 43930  40 35610  45 29020
				50 23770  55 19580  60 16200>;
			q_max_pos_50 = <0xab7>;
			q_max_pos_25 = <0xa93>;
			q_max_pos_0 = <0x348>;
			q_max_neg_10 = <0x327>;
			q_max_pos_50_h_current = <0xa80>;
			q_max_pos_25_h_current = <0xa5d>;
			q_max_pos_0_h_current = <0x337>;
			q_max_neg_10_h_current = <0x317>;
			car_tune_value = <0x76>;
			battery_profile_t0_num = <0x52>;
			battery_profile_t0 = <0x0 0x10cf 0x6 0x10b9 0xd 0x10a5 0x12 0x1090 0x19 0x1079 0x1f 0x1062
				    0x26 0x1049 0x2c 0x1031 0x33 0x1015 0x38 0xff8 0x3e 0xfe4 0x45 0xfcf
				    0x4b 0xfb3 0x52 0xf9d 0x57 0xf8d 0x5e 0xf7f 0x64 0xf74 0x6b 0xf66
				    0x71 0xf59 0x76 0xf49 0x7d 0xf37 0x80 0xf28 0x87 0xf1d 0x8d 0xf11
				    0x93 0xf08 0x9a 0xeff 0x9f 0xef6 0xa6 0xeef 0xac 0xeea 0xb3 0xee3
				    0xb9 0xede 0xc0 0xed8 0xc5 0xed4 0xcb 0xecf 0xd2 0xecb 0xd8 0xec5
				    0xdf 0xebf 0xe4 0xeba 0xeb 0xeb0 0xf1 0xea8 0xf8 0xe9e 0xfe 0xe93
				    0x103 0xe89 0x10a 0xe81 0x110 0xe78 0x117 0xe72 0x11d 0xe68 0x124 0xe51
				    0x129 0xe1d 0x130 0xdc6 0x133 0xd8a 0x136 0xd74 0x139 0xd60 0x139 0xd4c>;
			battery_profile_t1_num = <0x52>;
			battery_profile_t1 = <0x0 0x10dc 0x7 0x10bb 0xc 0x1094 0x14 0x1072 0x16 0x1059 0x1d 0x1044
				    0x22 0x1030 0x29 0x1020 0x31 0x100d 0x36 0xffd 0x3d 0xff0 0x3f 0xfe5
				    0x47 0xfcf 0x4e 0xfb7 0x53 0xfa3 0x5a 0xf95 0x5f 0xf89 0x64 0xf7f
				    0x69 0xf73 0x70 0xf64 0x78 0xf53 0x7c 0xf43 0x84 0xf33 0x8b 0xf25
				    0x8d 0xf18 0x95 0xf0f 0x9a 0xf06 0xa1 0xefd 0xa6 0xef7 0xad 0xeef
				    0xb5 0xee7 0xb7 0xee3 0xbe 0xedc 0xc3 0xed7 0xca 0xed2 0xd2 0xece
				    0xd7 0xec9 0xde 0xec6 0xe0 0xec2 0xe8 0xebd 0xed 0xeb8 0xf4 0xeb1
				    0xfb 0xea9 0x100 0xe9e 0x105 0xe8f 0x10a 0xe80 0x111 0xe78 0x116 0xe75
				    0x11d 0xe72 0x125 0xe6c 0x12a 0xe60 0x12e 0xe29 0x133 0xdc8 0x13b 0xd90
				    0x142 0xd4b 0x144 0xcfb 0x144 0xcc3 0x144 0xc9e 0x147 0xc83 0x147 0xc6c
				    0x147 0xc55 0x147 0xc45 0x147 0xc34 0x147 0xc25 0x147 0xc18 0x147 0xc0c
				    0x147 0xc07 0x147 0xbfb 0x147 0xbf2 0x147 0xbe7 0x147 0xbe1 0x147 0xbd8
				    0x147 0xbd5 0x147 0xbca 0x147 0xbc0 0x147 0xbba 0x147 0xbbb 0x147 0xbb3
				    0x147 0xba9 0x147 0xba7 0x147 0xba3 0x147 0xb97>;
			battery_profile_t2_num = <0x52>;
			battery_profile_t2 = <0x0 0x10e8 0x2 0x10cf 0x4 0x10bb 0x5 0x10a7 0x7 0x1095 0x9 0x1083
				    0xb 0x1071 0xd 0x105d 0xe 0x104d 0x10 0x103b 0x13 0x102a 0x15 0x1019
				    0x16 0x1008 0x18 0xff7 0x1a 0xfe8 0x1c 0xfda 0x1e 0xfc9 0x1f 0xfb9
				    0x21 0xfab 0x23 0xf9c 0x25 0xf8f 0x27 0xf84 0x28 0xf76 0x2a 0xf69
				    0x2c 0xf56 0x2e 0xf43 0x30 0xf31 0x31 0xf24 0x34 0xf19 0x36 0xf0e
				    0x38 0xf06 0x39 0xf00 0x3b 0xef8 0x3d 0xef0 0x3f 0xeea 0x41 0xee5
				    0x42 0xedd 0x44 0xed9 0x46 0xed2 0x48 0xecd 0x4a 0xec8 0x4b 0xec2
				    0x4d 0xebc 0x4f 0xeb5 0x51 0xea9 0x54 0xea1 0x55 0xe95 0x57 0xe85
				    0x59 0xe73 0x5b 0xe6c 0x5c 0xe6b 0x5e 0xe69 0x60 0xe67 0x62 0xe54
				    0x64 0xe0d 0x65 0xda9 0x67 0xd3f 0x68 0xc55 0x69 0xc01 0x69 0xbce
				    0x69 0xbb0 0x69 0xb99 0x69 0xb8e 0x69 0xb82 0x69 0xb76 0x69 0xb6d
				    0x69 0xb61 0x69 0xb5e 0x69 0xb54 0x69 0xb4b 0x69 0xb4b 0x69 0xb4b
				    0x69 0xb4b 0x69 0xb4b 0x69 0xb4b 0x69 0xb4b 0x69 0xb4b 0x69 0xb4b
				    0x69 0xb4b 0x69 0xb4b 0x69 0xb4b 0x69 0xb4b>;
			battery_profile_t3_num = <0x52>;
			battery_profile_t3 = <0x0 0x10eb 0x2 0x10d1 0x3 0x10bc 0x5 0x10a9 0x7 0x1094 0xa 0x1081
				    0xb 0x106e 0xd 0x105c 0xf 0x104a 0x10 0x1039 0x12 0x1027 0x14 0x1017
				    0x16 0x1006 0x17 0xff5 0x1a 0xfe5 0x1c 0xfd6 0x1d 0xfc6 0x1f 0xfb7
				    0x21 0xfaa 0x23 0xf9c 0x24 0xf90 0x26 0xf82 0x28 0xf76 0x29 0xf6b
				    0x2c 0xf5e 0x2e 0xf51 0x2f 0xf40 0x31 0xf2c 0x33 0xf1c 0x35 0xf11
				    0x36 0xf08 0x38 0xefe 0x3b 0xef8 0x3c 0xef0 0x3e 0xee9 0x40 0xee3
				    0x42 0xede 0x43 0xed8 0x45 0xed2 0x47 0xece 0x48 0xec8 0x4a 0xec1
				    0x4d 0xeb3 0x4f 0xeae 0x50 0xea6 0x52 0xe9e 0x54 0xe95 0x55 0xe8b
				    0x57 0xe7d 0x59 0xe6e 0x5b 0xe5e 0x5d 0xe5c 0x5f 0xe5b 0x61 0xe5a
				    0x62 0xe55 0x64 0xe29 0x66 0xddb 0x68 0xda7 0x69 0xd82 0x6b 0xd03
				    0x6d 0xc44 0x6d 0xc06 0x6d 0xbd9 0x6d 0xbb9 0x6d 0xba4 0x6e 0xb90
				    0x6e 0xb80 0x6e 0xb74 0x6e 0xb69 0x6e 0xb61 0x6e 0xb57 0x6e 0xb53
				    0x6e 0xb49 0x6e 0xb49 0x6e 0xb49 0x6e 0xb49 0x6e 0xb49 0x6e 0xb49
				    0x6e 0xb49 0x6e 0xb49 0x6e 0xb49 0x6e 0xb49>;
			r_profile_t0_num = <0x52>;
			r_profile_t0 = <0x198 0x10cf 0x198 0x10b9 0x19f 0x10a5 0x1a9 0x1090 0x1ae 0x1079 0x1b8 0x1062
				    0x1cf 0x1049 0x1ea 0x1031 0x20d 0x1015 0x23d 0xff8 0x267 0xfe4 0x28a 0xfcf
				    0x2a3 0xfb3 0x2ad 0xf9d 0x2c1 0xf8d 0x2c9 0xf7f 0x2d0 0xf74 0x2dd 0xf66
				    0x2d8 0xf59 0x2e2 0xf49 0x2d5 0xf37 0x2df 0xf28 0x2e9 0xf1d 0x2ec 0xf11
				    0x2f8 0xf08 0x305 0xeff 0x30f 0xef6 0x323 0xeef 0x334 0xeea 0x343 0xee3
				    0x35f 0xede 0x378 0xed8 0x387 0xed4 0x39d 0xecf 0x3bb 0xecb 0x3cf 0xec5
				    0x3e8 0xebf 0x40b 0xeba 0x422 0xeb0 0x442 0xea8 0x451 0xe9e 0x46f 0xe93
				    0x490 0xe89 0x4ba 0xe81 0x4e7 0xe78 0x541 0xe72 0x596 0xe68 0x5ee 0xe51
				    0x622 0xe1d 0x652 0xdc6 0x684 0xd8a 0x64d 0xd74 0x61b 0xd60 0x5e6 0xd4c
				    0x5b4 0xd35 0x578 0xd1d 0x535 0xd04 0x503 0xcee 0x4d1 0xcdb 0x4ae 0xcca
				    0x483 0xcbb 0x468 0xcad 0x445 0xca2 0x433 0xc95 0x41d 0xc8c 0x3ff 0xc84
				    0x3fa 0xc79 0x3ed 0xc72 0x3d2 0xc6b 0x3c0 0xc60 0x3ac 0xc5a 0x37f 0xc55
				    0x37a 0xc4f 0x35f 0xc47 0x39d 0xc3d 0x37d 0xc35 0x37d 0xc35 0x37d 0xc35
				    0x37d 0xc35 0x37d 0xc35 0x37d 0xc35 0x37d 0xc35>;
			r_profile_t1_num = <0x52>;
			r_profile_t1 = <0x102 0x10dc 0x102 0x10bb 0x116 0x1094 0x12f 0x1072 0x14d 0x1059 0x157 0x1044
				    0x15e 0x1030 0x16d 0x1020 0x172 0x100d 0x172 0xffd 0x17c 0xff0 0x193 0xfe5
				    0x18b 0xfcf 0x193 0xfb7 0x193 0xfa3 0x19d 0xf95 0x1a2 0xf89 0x1a4 0xf7f
				    0x1a7 0xf73 0x19f 0xf64 0x19a 0xf53 0x190 0xf43 0x189 0xf33 0x189 0xf25
				    0x184 0xf18 0x18b 0xf0f 0x193 0xf06 0x195 0xefd 0x19f 0xef7 0x1a9 0xeef
				    0x1ae 0xee7 0x1bb 0xee3 0x1c2 0xedc 0x1d1 0xed7 0x1db 0xed2 0x1e3 0xece
				    0x1ea 0xec9 0x1f7 0xec6 0x208 0xec2 0x215 0xebd 0x221 0xeb8 0x233 0xeb1
				    0x24c 0xea9 0x258 0xe9e 0x260 0xe8f 0x267 0xe80 0x27b 0xe78 0x29e 0xe75
				    0x2c6 0xe72 0x2fd 0xe6c 0x348 0xe60 0x370 0xe29 0x393 0xdc8 0x438 0xd90
				    0x52b 0xd4b 0x523 0xcfb 0x49c 0xcc3 0x438 0xc9e 0x3f2 0xc83 0x3be 0xc6c
				    0x39d 0xc55 0x378 0xc45 0x35c 0xc34 0x32a 0xc25 0x314 0xc18 0x2fd 0xc0c
				    0x2bc 0xc07 0x2e9 0xbfb 0x2a8 0xbf2 0x2ad 0xbe7 0x28a 0xbe1 0x2ab 0xbd8
				    0x267 0xbd5 0x283 0xbca 0x294 0xbc0 0x27b 0xbba 0x212 0xbbb 0x280 0xbb3
				    0x253 0xba9 0x217 0xba7 0x1cf 0xba3 0x258 0xb97>;
			r_profile_t2_num = <0x52>;
			r_profile_t2 = <0x9b 0x10e8 0x9b 0x10cf 0x9b 0x10bb 0x9e 0x10a7 0x9e 0x1095 0xa3 0x1083
				    0xa5 0x1071 0xa5 0x105d 0xaa 0x104d 0xaa 0x103b 0xad 0x102a 0xad 0x1019
				    0xad 0x1008 0xb2 0xff7 0xb4 0xfe8 0xb9 0xfda 0xbc 0xfc9 0xbe 0xfb9
				    0xc8 0xfab 0xc8 0xf9c 0xcd 0xf8f 0xda 0xf84 0xd7 0xf76 0xd7 0xf69
				    0xc8 0xf56 0xbc 0xf43 0xad 0xf31 0xa8 0xf24 0xa3 0xf19 0xa0 0xf0e
				    0xa3 0xf06 0xa8 0xf00 0xaa 0xef8 0xaa 0xef0 0xaa 0xeea 0xb2 0xee5
				    0xaf 0xedd 0xb7 0xed9 0xb4 0xed2 0xb7 0xecd 0xb9 0xec8 0xb7 0xec2
				    0xb9 0xebc 0xb7 0xeb5 0xad 0xea9 0xad 0xea1 0xad 0xe95 0xad 0xe85
				    0xad 0xe73 0xaa 0xe6c 0xaf 0xe6b 0xb9 0xe69 0xc6 0xe67 0xcd 0xe54
				    0xd0 0xe0d 0xf0 0xda9 0x111 0xd3f 0x38c 0xc55 0x2c1 0xc01 0x253 0xbce
				    0x201 0xbb0 0x1d1 0xb99 0x19d 0xb8e 0x17c 0xb82 0x170 0xb76 0x168 0xb6d
				    0x14f 0xb61 0x113 0xb5e 0x13b 0xb54 0x11b 0xb4b 0x11b 0xb4b 0x11b 0xb4b
				    0x11b 0xb4b 0x11b 0xb4b 0x11b 0xb4b 0x11b 0xb4b 0x11b 0xb4b 0x11b 0xb4b
				    0x11b 0xb4b 0x11b 0xb4b 0x11b 0xb4b 0x11b 0xb4b>;
			r_profile_t3_num = <0x52>;
			r_profile_t3 = <0x7b 0x10eb 0x7b 0x10d1 0x80 0x10bc 0x82 0x10a9 0x82 0x1094 0x82 0x1081
				    0x80 0x106e 0x7d 0x105c 0x82 0x104a 0x85 0x1039 0x85 0x1027 0x8a 0x1017
				    0x8a 0x1006 0x8c 0xff5 0x8c 0xfe5 0x8f 0xfd6 0x8c 0xfc6 0x8f 0xfb7
				    0x94 0xfaa 0x99 0xf9c 0x9b 0xf90 0x9b 0xf82 0xa5 0xf76 0xaf 0xf6b
				    0xaf 0xf5e 0xb2 0xf51 0xaa 0xf40 0x94 0xf2c 0x87 0xf1c 0x87 0xf11
				    0x85 0xf08 0x85 0xefe 0x87 0xef8 0x87 0xef0 0x87 0xee9 0x8f 0xee3
				    0x91 0xede 0x94 0xed8 0x91 0xed2 0x99 0xece 0x96 0xec8 0x96 0xec1
				    0x85 0xeb3 0x8f 0xeae 0x8c 0xea6 0x8a 0xe9e 0x87 0xe95 0x87 0xe8b
				    0x85 0xe7d 0x85 0xe6e 0x82 0xe5e 0x82 0xe5c 0x8a 0xe5b 0x94 0xe5a
				    0xa0 0xe55 0x9e 0xe29 0xaa 0xddb 0xd0 0xda7 0xdc 0xd82 0x109 0xd03
				    0x357 0xc44 0x2d5 0xc06 0x258 0xbd9 0x210 0xbb9 0x1cc 0xba4 0x190 0xb90
				    0x17c 0xb80 0x163 0xb74 0x13b 0xb69 0x12f 0xb61 0x134 0xb57 0xff 0xb53
				    0x111 0xb49 0x111 0xb49 0x111 0xb49 0x111 0xb49 0x111 0xb49 0x111 0xb49
				    0x111 0xb49 0x111 0xb49 0x111 0xb49 0x111 0xb49>;
		};
		scpdvfs@0 {
			pinctrl-names = "default", "scp_gpio_off", "scp_gpio_on";
			pinctrl-0 = <&nk_default>;
			pinctrl-1 = <&nk_scp_gpio_off>;
			pinctrl-2 = <&nk_scp_gpio_on>;
			status = "okay";
		};
		ap2c2k_ccif@1020b000 {
			ccif,capability = <0x0>;
		};
		adc_hw@11001000 {
			adc_channel@ {
				compatible = "mediatek,adc_channel";
				mediatek,temperature0 = <0x0>;
				mediatek,temperature1 = <0x1>;
				mediatek,adc_fdd_rf_params_dynamic_custom_ch = <0x2>;
				status = "okay";
			};
		};
		i2c@11007000 {
			#address-cells = <0x1>;
			#size-cells = <0x0>;
			clock-frequency = <0x61a80>;
			mediatek,use-open-drain;
			sw_charger@6b {
				compatible = "mediatek,sw_charger";
				reg = <0x6b>;
				status = "okay";
			};
			i2c_lcd_bias@3e {
				compatible = "mediatek,i2c_lcd_bias";
				reg = <0x3e>;
				status = "okay";
			};
			buck_boost@70 {
				compatible = "mediatek,buck_boost";
				reg = <0x70>;
				status = "okay";
			};
			strobe_main@63 {
				compatible = "mediatek,strobe_main";
				reg = <0x63>;
				status = "okay";
			};
			speaker_amp@34 {
				compatible = "mediatek,speaker_amp";
				reg = <0x34>;
				status = "okay";
			};
		};
		i2c@11008000 {
			#address-cells = <0x1>;
			#size-cells = <0x0>;
			clock-frequency = <0x61a80>;
			mediatek,use-open-drain;
			usb_type_c@3d {
				compatible = "mediatek,usb_type_c";
				reg = <0x3d>;
				status = "okay";
			};
			msensor@2e {
				compatible = "mediatek,msensor";
				reg = <0x2e>;
				status = "okay";
				/* nikel: YAS537 (stock cust_mag: yamaha537, direction 2).
				 * Can be changed live: echo 0..7 > .../msensor/layout */
				i2c_num = <1>;
				i2c_addr = <0x2e 0>;
				direction = <2>;
				power_id = <0xffff>;
				power_vol = <0>;
				is_batch_supported = <0>;
			};
			gyro@69 {
				compatible = "mediatek,gyro";
				reg = <0x69>;
				status = "okay";
				/* nikel: placeholder client only; the gyro driver talks
				 * to the BMI160 at 0x68 through the accel driver */
				i2c_num = <1>;
				direction = <1>;	/* as stock cust_gyro (mediatek,bmi160_gyro) */
				power_id = <0xffff>;
				power_vol = <0>;
				firlen = <0>;
				is_batch_supported = <0>;
			};
			gsensor@68 {
				compatible = "mediatek,gsensor";
				reg = <0x68>;
				status = "okay";
				/* nikel: BMI160 (accel + gyro in one chip). direction
				 * maps chip axes to the screen; tune after first test */
				i2c_num = <1>;
				i2c_addr = <0x68 0 0 0>;
				direction = <1>;	/* tested on the phone: 3 (stock value) swaps left/right */
				power_id = <0xffff>;
				power_vol = <0>;
				firlen = <0>;
				is_batch_supported = <0>;
			};
			barometer@77 {
				compatible = "mediatek,barometer";
				reg = <0x77>;
				status = "okay";
			};
			alsps@53 {
				compatible = "mediatek,alsps";
				reg = <0x53>;
				status = "okay";
				/* nikel: LTR-579, values from the stock cust_alsps node.
				 * The driver uses 15 levels / 16 values, so the stock
				 * 18-step table is thinned to keep its full range. */
				i2c_num = <1>;
				i2c_addr = <0x53 0 0 0>;
				power_id = <0xffff>;
				power_vol = <0>;
				polling_mode_ps = <1>;
				polling_mode_als = <1>;
				als_level = <1 4 10 30 120 255 380 650 900 1350 2200 3500 6000 20000 50000>;
				als_value = <0 5 10 30 80 225 320 550 800 1250 2000 3000 5000 7500 24000 30000>;
				ps_threshold_high = <0x3c>;
				ps_threshold_low = <0x28>;
				is_batch_supported_ps = <0>;
				is_batch_supported_als = <0>;
			};
			humidity@5f {
				compatible = "mediatek,humidity";
				reg = <0x5f>;
				status = "okay";
			};
			chargepump@62 {
				compatible = "mediatek,chargepump";
				reg = <0x62>;
				status = "okay";
			};
			msensor1@0d {
				compatible = "mediatek,msensor1";
				reg = <0xd>;
				status = "okay";
			};
		};
		i2c@11009000 {
			#address-cells = <0x1>;
			#size-cells = <0x0>;
			clock-frequency = <0x61a80>;
			mediatek,use-open-drain;
			camera_main_hw@36 {
				compatible = "mediatek,camera_main_hw";
				reg = <0x36>;
				status = "okay";
			};
		};
		spi@1100a000 {
			#address-cells = <0x1>;
			#size-cells = <0x0>;
			goodix-fp@1 {
				compatible = "goodix,goodix-fp";
				reg = <0x0>;
				spi-max-frequency = <0x7a1200>;
				netlink-event = <0x1a>;
				status = "okay";
			};
		};
		i2c@1100d000 {
			#address-cells = <0x1>;
			#size-cells = <0x0>;
			clock-frequency = <0x61a80>;
			mediatek,use-open-drain;
		};
		i2c@1100e000 {
			#address-cells = <0x1>;
			#size-cells = <0x0>;
			clock-frequency = <0x33e140>;
			mediatek,use-push-pull;
			vproc_buck@68 {
				compatible = "mediatek,vproc_buck";
				reg = <0x68>;
				status = "okay";
			};
		};
		i2c@11010000 {
			#address-cells = <0x1>;
			#size-cells = <0x0>;
			clock-frequency = <0x33e140>;
			mediatek,use-push-pull;
			vgpu_buck@60 {
				compatible = "mediatek,vgpu_buck";
				reg = <0x60>;
				status = "okay";
			};
		};
		i2c@11011000 {
			#address-cells = <0x1>;
			#size-cells = <0x0>;
			clock-frequency = <0x61a80>;
			mediatek,use-open-drain;
			cap_touch@38 {
				compatible = "mediatek,cap_touch";
				reg = <0x38>;
				status = "okay";
			};
			atmel_cap_touch@4a {
				compatible = "mediatek,atmel_cap_touch";
				reg = <0x4a>;
				status = "okay";
			};
			gt_cap_touch@5d {
				compatible = "mediatek,gt_cap_touch";
				reg = <0x5d>;
				status = "okay";
			};
		};
		spi@11012000 {
			#address-cells = <0x1>;
			#size-cells = <0x0>;
			pinctrl-names = "spi1_gpio_def", "spi1_cs_set", "spi1_cs_clr", "spi1_clk_set", "spi1_clk_clr", "spi1_miso_set", "spi1_miso_clr", "spi1_mosi_set", "spi1_mosi_clr";
			pinctrl-0 = <&nk_spi1_gpio_default>;
			pinctrl-1 = <&nk_spi1_cs_set_gpio237>;
			pinctrl-2 = <&nk_spi1_cs_clear_gpio237>;
			pinctrl-3 = <&nk_spi1_clk_set_gpio234>;
			pinctrl-4 = <&nk_spi1_clk_clear_gpio234>;
			pinctrl-5 = <&nk_spi1_miso_set_gpio235>;
			pinctrl-6 = <&nk_spi1_miso_clear_gpio235>;
			pinctrl-7 = <&nk_spi1_mosi_set_gpio236>;
			pinctrl-8 = <&nk_spi1_mosi_clear_gpio236>;
			status = "okay";
			fpc1145@0 {
				compatible = "fpc,fpc1020";
				reg = <0x0>;
				spi-max-frequency = <0xf42400>;
				fpc,gpio_reset = <0x2b>;
			};
		};
		i2c@11013000 {
			#address-cells = <0x1>;
			#size-cells = <0x0>;
			clock-frequency = <0x493e0>;
			mediatek,use-open-drain;
			camera_main@36 {
				compatible = "mediatek,camera_main";
				reg = <0x36>;
				status = "okay";
			};
			camera_main_af@72 {
				compatible = "mediatek,camera_main_af";
				reg = <0x72>;
				status = "okay";
			};
		};
		i2c@11014000 {
			#address-cells = <0x1>;
			#size-cells = <0x0>;
			clock-frequency = <0x61a80>;
			mediatek,use-open-drain;
			camera_sub@2d {
				compatible = "mediatek,camera_sub";
				reg = <0x2d>;
				status = "okay";
			};
			camera_sub_af@0c {
				compatible = "mediatek,camera_sub_af";
				reg = <0xc>;
				status = "okay";
			};
			camera_main_two@30 {
				compatible = "mediatek,camera_main_two";
				reg = <0x30>;
				status = "okay";
			};
		};
		spi@11018000 {
			#address-cells = <0x1>;
			#size-cells = <0x0>;
			leadcore-fp@1 {
				compatible = "leadcore,leadcore-fp";
				reg = <0x0>;
				spi-max-frequency = <0x7a1200>;
				netlink-event = <0x1a>;
				status = "okay";
			};
		};
		i2c@1101c000 {
			#address-cells = <0x1>;
			#size-cells = <0x0>;
			clock-frequency = <0x61a80>;
			mediatek,use-open-drain;
			nfc@28 {
				compatible = "mediatek,nfc";
				reg = <0x28>;
				status = "okay";
			};
		};
		irtx@1101d000 {
			pwm_ch = <0x0>;
			pinctrl-names = "irtx_gpio_default", "irtx_gpio_led_set";
			pinctrl-0 = <&nk_irtx_gpio_led_def_gpio135>;
			pinctrl-1 = <&nk_irtx_gpio_led_set_gpio135>;
			status = "okay";
		};
		mt_soc_dl1_pcm@11220000 {
			pinctrl-names = "aud_clk_mosi_off", "aud_clk_mosi_on", "aud_smartpa_mode0", "aud_smartpa_mode1", "aud_smartpa_mode3", "aud_tdm_mode0", "aud_tdm_mode1", "hpdepop-pullhigh", "hpdepop-pulllow", "aud_dat_miso_off", "aud_dat_miso_on", "aud_dat_mosi_off", "aud_dat_mosi_on", "vow_dat_miso_off", "vow_dat_miso_on", "vow_clk_miso_off", "vow_clk_miso_on", "anc_dat_mosi_off", "anc_dat_mosi_on", "aud_extamp_high", "aud_extamp_low", "hpdepop-pullhigh_e2", "hpdepop-pulllow_e2";
			pinctrl-0 = <&nk_aud_clk_mosi_off>;
			pinctrl-1 = <&nk_aud_clk_mosi_on>;
			pinctrl-2 = <&nk_aud_pins_smartpa_mode0>;
			pinctrl-3 = <&nk_aud_pins_smartpa_mode1>;
			pinctrl-4 = <&nk_aud_pins_smartpa_mode3>;
			pinctrl-5 = <&nk_aud_pins_tdm_mode0>;
			pinctrl-6 = <&nk_aud_pins_tdm_mode1>;
			pinctrl-7 = <&nk_audhpdepophigh>;
			pinctrl-8 = <&nk_audhpdepoplow>;
			pinctrl-9 = <&nk_aud_dat_miso_off>;
			pinctrl-10 = <&nk_aud_dat_miso_on>;
			pinctrl-11 = <&nk_aud_dat_mosi_off>;
			pinctrl-12 = <&nk_aud_dat_mosi_on>;
			pinctrl-13 = <&nk_vow_dat_miso_off>;
			pinctrl-14 = <&nk_vow_dat_miso_on>;
			pinctrl-15 = <&nk_vow_clk_miso_off>;
			pinctrl-16 = <&nk_vow_clk_miso_on>;
			pinctrl-17 = <&nk_anc_dat_mosi_off>;
			pinctrl-18 = <&nk_anc_dat_mosi_on>;
			pinctrl-19 = <&nk_aud_extamp_high>;
			pinctrl-20 = <&nk_aud_extamp_low>;
			/*
			 * SHIFT's AudDrv_Gpio.c renames the headphone de-pop states to
			 * "*_e2" when LK reports an FAN53526 buck (nikel's LK does:
			 * extbuck_fan53526_exist = 1). Without these names the lookup
			 * fails and the driver BUG()s on the first audio playback
			 * (first Lineage boot: kernel panic in AudDrv_GPIO_Select).
			 * Same pins as hpdepop-pullhigh/-pulllow.
			 */
			pinctrl-21 = <&nk_audhpdepophigh>;
			pinctrl-22 = <&nk_audhpdepoplow>;
			status = "okay";
		};
		usb3@11270000 {
			pinctrl-names = "iddig_default", "iddig_init";
			pinctrl-0 = <&nk_iddig_default>;
			pinctrl-1 = <&nk_iddig_init>;
			status = "okay";
		};
		usb3_xhci@11270000 {
			pinctrl-names = "drvvbus_default", "drvvbus_low", "drvvbus_high";
			pinctrl-0 = <&nk_drvvbus_default>;
			pinctrl-1 = <&nk_drvvbus_low>;
			pinctrl-2 = <&nk_drvvbus_high>;
			status = "okay";
		};
		usb_c_pinctrl@0 {
			pinctrl-names = "usb_default", "redriver_c1_init", "redriver_c1_low", "redriver_c1_hiz", "redriver_c1_high", "redriver_c2_init", "redriver_c2_low", "redriver_c2_hiz", "redriver_c2_high", "fusb340_noe_init", "fusb340_noe_low", "fusb340_noe_high", "fusb340_sel_init", "fusb340_sel_low", "fusb340_sel_high";
			pinctrl-0 = <&nk_usb_default>;
			pinctrl-1 = <&nk_gpio197_redriver_c1_init>;
			pinctrl-2 = <&nk_gpio197_redriver_c1_low>;
			pinctrl-3 = <&nk_gpio197_redriver_c1_highz>;
			pinctrl-4 = <&nk_gpio197_redriver_c1_high>;
			pinctrl-5 = <&nk_gpio196_redriver_c2_init>;
			pinctrl-6 = <&nk_gpio196_redriver_c2_low>;
			pinctrl-7 = <&nk_gpio196_redriver_c2_highz>;
			pinctrl-8 = <&nk_gpio196_redriver_c2_high>;
			pinctrl-9 = <&nk_gpio251_fusb340_noe_init>;
			pinctrl-10 = <&nk_gpio251_fusb340_noe_low>;
			pinctrl-11 = <&nk_gpio251_fusb340_noe_high>;
			pinctrl-12 = <&nk_gpio252_fusb340_sel_init>;
			pinctrl-13 = <&nk_gpio252_fusb340_sel_low>;
			pinctrl-14 = <&nk_gpio252_fusb340_sel_high>;
			status = "okay";
		};
		lcm_mode {
			pinctrl-names = "default", "lcm_mode_00", "lcm_mode_01", "lcm_mode_02", "lcm_mode_03", "lcm_mode_04", "lcm_mode_05", "lcm_mode_07";
			pinctrl-0 = <&nk_lcm_mode_default>;
			pinctrl-1 = <&nk_lcm_mode_0>;
			pinctrl-2 = <&nk_lcm_mode_1>;
			pinctrl-3 = <&nk_lcm_mode_2>;
			pinctrl-4 = <&nk_lcm_mode_3>;
			pinctrl-5 = <&nk_lcm_mode_4>;
			pinctrl-6 = <&nk_lcm_mode_5>;
			pinctrl-8 = <&nk_lcm_mode_7>;
			lcm_power_gpio = <&pio 0x41 0x0>;
			lcm_bl_gpio = <&pio 0x3e 0x0>;
			status = "okay";
		};
		consys@18070000 {
			pinctrl-names = "default", "gps_lna_state_init", "gps_lna_state_oh", "gps_lna_state_ol";
			pinctrl-0 = <&nk_default>;
			pinctrl-1 = <&nk_gpslna_0>;
			pinctrl-2 = <&nk_gpslna_1>;
			pinctrl-3 = <&nk_gpslna_2>;
			status = "okay";
		};
		kd_camera_hw1@1a040000 {
			vcama_main2-supply = <&mt_pmic_vcama_ldo_reg>;
			vcama_sub-supply = <&mt_pmic_vcama_ldo_reg>;
			vcamaf_main2-supply = <&mt_pmic_vldo28_ldo_reg>;
			vcamaf_sub-supply = <&mt_pmic_vldo28_ldo_reg>;
			vcamd_main2-supply = <&mt_pmic_vgp3_ldo_reg>;
			vcamd_sub-supply = <&mt_pmic_vgp3_ldo_reg>;
			vcamio_main2-supply = <&mt_pmic_vcamio_ldo_reg>;
			vcamio_sub-supply = <&mt_pmic_vcamio_ldo_reg>;
			status = "okay";
			pinctrl-names = "default", "cam0_rst0", "cam0_rst1", "cam0_pnd0", "cam0_pnd1", "cam1_rst0", "cam1_rst1", "cam1_pnd0", "cam1_pnd1", "cam2_rst0", "cam2_rst1", "cam2_pnd0", "cam2_pnd1", "cam_ldo_vcama_0", "cam_ldo_vcama_1", "cam_ldo_vcamd_0", "cam_ldo_vcamd_1", "cam2_ldo_vcama_0", "cam2_ldo_vcama_1";
			pinctrl-0 = <&nk_camdefault>;
			pinctrl-1 = <&nk_cam0_0>;
			pinctrl-2 = <&nk_cam0_1>;
			pinctrl-3 = <&nk_cam0_2>;
			pinctrl-4 = <&nk_cam0_3>;
			pinctrl-5 = <&nk_cam1_0>;
			pinctrl-6 = <&nk_cam1_1>;
			pinctrl-7 = <&nk_cam1_2>;
			pinctrl-8 = <&nk_cam1_3>;
			pinctrl-9 = <&nk_cam2_0>;
			pinctrl-10 = <&nk_cam2_1>;
			pinctrl-11 = <&nk_cam2_2>;
			pinctrl-12 = <&nk_cam2_3>;
			pinctrl-13 = <&nk_cam0_vcama0>;
			pinctrl-14 = <&nk_cam1_vcama1>;
			pinctrl-15 = <&nk_cam0_vcamd0>;
			pinctrl-16 = <&nk_cam1_vcamd1>;
			pinctrl-17 = <&nk_cam2_vcama0>;
			pinctrl-18 = <&nk_cam2_vcama1>;
		};
		mrdump_ext_rst {
			interrupt-parent = <&eintc>;
			interrupts = <0x1d 0x8>;
			debounce = <0x1d 0x7d000>;
			status = "okay";
		};
		mtkfb@0 {
			pinctrl-names = "mode_te_gpio", "mode_te_te", "lcm_rst_out0_gpio", "lcm_rst_out1_gpio", "lcd_bias_enp_gpio_high", "lcd_bias_enp_gpio_low", "lcd_pwr_en_gpio_high", "lcd_pwr_en_gpio_low", "lcd_bias_enn_gpio_high", "lcd_bias_enn_gpio_low", "lcd_backlight_en_gpio_high", "lcd_backlight_en_gpio_low";
			pinctrl-0 = <&nk_mode_te_gpio>;
			pinctrl-1 = <&nk_mode_te_te>;
			pinctrl-2 = <&nk_lcm_rst_out0_gpio>;
			pinctrl-3 = <&nk_lcm_rst_out1_gpio>;
			pinctrl-4 = <&nk_lcd_bias_enp_gpio_high>;
			pinctrl-5 = <&nk_lcd_bias_enp_gpio_low>;
			pinctrl-6 = <&nk_lcd_pwr_en_gpio_high>;
			pinctrl-7 = <&nk_lcd_pwr_en_gpio_low>;
			pinctrl-8 = <&nk_lcd_bias_enn_gpio_high>;
			pinctrl-9 = <&nk_lcd_bias_enn_gpio_low>;
			pinctrl-10 = <&nk_lcd_backlight_en_gpio_high>;
			pinctrl-11 = <&nk_lcd_backlight_en_gpio_low>;
			status = "okay";
		};
		fpc {
			interrupt-parent = <&eintc>;
			interrupts = <0x56 0x1>;
			debounce = <0x56 0x0>;
			status = "okay";
			pinctrl-names = "default", "reset_high", "reset_low", "power_on", "power_off", "gf_irq", "tas_mod1_high", "tas_mod1_low", "tas_mod2_high", "tas_mod2_low", "tas_mod1_bpi", "tas_mod2_bpi";
			pinctrl-0 = <&nk_state_default>;
			pinctrl-1 = <&nk_state_reset_high>;
			pinctrl-2 = <&nk_state_reset_low>;
			pinctrl-3 = <&nk_state_power_on>;
			pinctrl-4 = <&nk_state_power_off>;
			pinctrl-5 = <&nk_state_gf_irq>;
			pinctrl-6 = <&nk_state_tas_mod_switch1_high>;
			pinctrl-7 = <&nk_state_tas_mod_switch1_low>;
			pinctrl-8 = <&nk_state_tas_mod_switch2_high>;
			pinctrl-9 = <&nk_state_tas_mod_switch2_low>;
			pinctrl-10 = <&nk_state_tas_mod_switch1_bpi_mode>;
			pinctrl-11 = <&nk_state_tas_mod_switch2_bpi_mode>;
		};
		/* FPC1145 (TEE): drivers/input/misc/nikel_fpc_irq.c */
		fpc_interrupt@0 {
			compatible = "fpc,fpc_irq";
			status = "ok";
			input-device-name = "fpc_irq";
			fpc,event-type = <0x4>;
			fpc,event-code = <0x4>;
			interrupt-parent = <&eintc>;
			interrupts = <0x56 0x1>;
			fpc,irq-gpio = <&pio 0x56 0x0>;
			pinctrl-names = "default", "reset_high", "reset_low", "power_on", "power_off", "irq";
			pinctrl-0 = <&nk_state_default>;
			pinctrl-1 = <&nk_state_reset_high>;
			pinctrl-2 = <&nk_state_reset_low>;
			pinctrl-3 = <&nk_state_power_on>;
			pinctrl-4 = <&nk_state_power_off>;
			pinctrl-5 = <&nk_state_gf_irq>;
			fpc,gpio_irq = <0x56>;
			fpc,gpio_reset = <0x2b>;
			fpc,use_fpc2050 = <0x1>;
		};
		rf_clock_buffer@0 {
			status = "okay";
		};
		pmic_clock_buffer@0 {
			mediatek,clkbuf-quantity = <0x4>;
			mediatek,clkbuf-config = <0x0 0x0 0x0 0x0>;
			mediatek,clkbuf-drviving-current = <0x2 0x2 0x2 0x2>;
			status = "okay";
		};
		ext_buck_oc@ {
			status = "okay";
			interrupt-parent = <&eintc>;
			interrupts = <0x3d 0x8>;
			debounce = <0x3d 0x0>;
		};
		ext_buck_vproc@ {
			pinctrl-names = "da9214_gpio_default";
			pinctrl-0 = <&nk_da9214_gpio_def_gpio61>;
			status = "okay";
		};
		chr_stat@ {
			status = "okay";
			interrupt-parent = <&eintc>;
			interrupts = <0x42 0x8>;
			debounce = <0x42 0x0>;
		};
		otg_iddig@ {
			interrupt-parent = <&eintc>;
			interrupts = <0xb5 0x8>;
			debounce = <0xb5 0x0>;
			status = "okay";
		};
		touch@ {
			regulator-name = "vtouch";
			interrupt-parent = <&eintc>;
			interrupts = <0x55 0x2>;
			debounce = <0x55 0x0>;
			status = "okay";
			tpd-resolution = <0x438 0x780>;
			use-tpd-button = <0x1>;
			tpd-key-num = <0x3>;
			tpd-key-local = <0x8b 0xac 0x9e 0x0>;
			tpd-key-dim-local = <0xa0 0x834 0x64 0x28 0x21c 0x834 0x64 0x28 0x398 0x834 0x64 0x28
				    0x0 0x0 0x0 0x0>;
			tpd-max-touch-num = <0xa>;
			tpd-filter-enable = <0x1>;
			tpd-filter-pixel-density = <0x92>;
			tpd-filter-custom-prameters = <0x0 0x0 0x0 0x0 0x0 0x0 0x0 0x0 0x0 0x0 0x0 0x0>;
			tpd-filter-custom-speed = <0x0 0x0 0x0>;
			pinctrl-names = "default", "state_eint_as_int", "state_eint_output0", "state_eint_output1", "state_rst_output0", "state_rst_output1", "state_enable_regulator_output0", "state_enable_regulator_output1";
			pinctrl-0 = <&nk_eint0default>;
			pinctrl-1 = <&nk_eint_0>;
			pinctrl-2 = <&nk_eintoutput0>;
			pinctrl-3 = <&nk_eintoutput1>;
			pinctrl-4 = <&nk_rstoutput0>;
			pinctrl-5 = <&nk_rstoutput1>;
			pinctrl-6 = <&nk_regulator_en_output0>;
			pinctrl-7 = <&nk_regulator_en_output1>;
		};
		vow@ {
			compatible = "mediatek,vow";
		};
		accdet@ {
			interrupt-parent = <&eintc>;
			interrupts = <0x5c 0x4>;
			debounce = <0x5c 0x3e800>;
			status = "okay";
			accdet-mic-vol = <0x7>;
			headset-mode-setting = <0x500 0x500 0x1 0x1f0 0x800 0x800 0x20>;
			accdet-plugout-debounce = <0x1>;
			accdet-mic-mode = <0x1>;
			headset-three-key-threshold = <0x0 0x50 0x96 0x190>;
			headset-four-key-threshold = <0x0 0x3a 0x79 0xc0 0x190>;
			pinctrl-names = "default", "state_eint_as_int";
			pinctrl-0 = <&nk_accdetdefault>;
			pinctrl-1 = <&nk_accdeteint_0>;
		};
		flashlight@ {
			pinctrl-names = "default", "hwen_high", "hwen_low", "enm_high", "enm_low", "enf_high", "enf_low";
			pinctrl-0 = <&nk_default>;
			pinctrl-1 = <&nk_hwen_high>;
			pinctrl-2 = <&nk_hwen_low>;
			pinctrl-3 = <&nk_enm_high>;
			pinctrl-4 = <&nk_enm_low>;
			pinctrl-5 = <&nk_enf_high>;
			pinctrl-6 = <&nk_enf_low>;
			status = "okay";
		};
		nfc1@0 {
			compatible = "mediatek,pn66t_nfc_gpio";
			gpio-pvdden = <0x29>;
			gpio-eint = <0x5d>;
			gpio-seeint = <0x59>;
			gpio-ven = <0x3b>;
			gpio-dlreq = <0x27>;
			gpio-seen = <0x28>;
			gpio-serest = <0x2a>;
			pinctrl-names = "default", "eint_init", "se_eint_init", "ven_high", "ven_low", "dl_req_high", "dl_req_low", "se_en_high", "se_en_low", "pvdd_en_high", "pvdd_en_low", "se_rst_high", "se_rst_low";
			pinctrl-0 = <&nk_default>;
			pinctrl-1 = <&nk_st1_eint_init>;
			pinctrl-2 = <&nk_st1_se_eint_init>;
			pinctrl-3 = <&nk_st1_ven_high>;
			pinctrl-4 = <&nk_st1_ven_low>;
			pinctrl-5 = <&nk_st1_dl_req_high>;
			pinctrl-6 = <&nk_st1_dl_req_low>;
			pinctrl-7 = <&nk_st1_se_en_high>;
			pinctrl-8 = <&nk_st1_se_en_low>;
			pinctrl-9 = <&nk_st1_pvdd_en_high>;
			pinctrl-10 = <&nk_st1_pvdd_en_low>;
			pinctrl-11 = <&nk_st1_se_rst_high>;
			pinctrl-12 = <&nk_st1_se_rst_low>;
			status = "okay";
		};
		nfcC@0 {
			gpio-ven = <0x3c>;
			gpio-rst = <0x3b>;
			gpio-eint = <0x39>;
			gpio-irq = <0x3a>;
			gpio-osc = <0x64>;
			pinctrl-names = "default", "ven_high", "ven_low", "rst_high", "rst_low", "eint_high", "eint_low", "irq_init", "osc_init", "cs_low", "mo_low", "mi_low", "sck_low";
			pinctrl-0 = <&nk_default>;
			pinctrl-1 = <&nk_state_ven_high>;
			pinctrl-2 = <&nk_state_ven_low>;
			pinctrl-3 = <&nk_state_rst_high>;
			pinctrl-4 = <&nk_state_rst_low>;
			pinctrl-5 = <&nk_state_eint_high>;
			pinctrl-6 = <&nk_state_eint_low>;
			pinctrl-7 = <&nk_state_irq_init>;
			pinctrl-8 = <&nk_state_osc_init>;
			pinctrl-9 = <&nk_state_cs_low>;
			pinctrl-10 = <&nk_state_mo_low>;
			pinctrl-11 = <&nk_state_mi_low>;
			pinctrl-12 = <&nk_state_sck_low>;
			status = "okay";
		};
		irq_nfc1@ {
			interrupt-parent = <&eintc>;
			interrupts = <0x5d 0x4>;
			debounce = <0x5d 0x3e8>;
			status = "okay";
		};
		dsi_te {
			status = "okay";
			interrupt-parent = <&eintc>;
			interrupts = <0xb3 0x1>;
			debounce = <0xb3 0x0>;
		};
		i2c0@11007000 {
			bq24261@6b {
				compatible = "bq24261";
				reg = <0x6b>;
			};
			mt6306@64 {
				compatible = "mediatek,mt6306";
				reg = <0x64>;
			};
		};
		mmc0@default {
			pins_cmd {
				drive-strength = [01];
			};
			pins_dat {
				drive-strength = [01];
			};
			pins_clk {
				drive-strength = [01];
			};
			pins_rst {
				drive-strength = [01];
			};
			pins_ds {
				drive-strength = [01];
			};
		};
		mmc0@register_default {
			dat0rddly = [00];
			dat1rddly = [00];
			dat2rddly = [00];
			dat3rddly = [00];
			dat4rddly = [00];
			dat5rddly = [00];
			dat6rddly = [00];
			dat7rddly = [00];
			datwrddly = [00];
			cmdrrddly = [00];
			cmdrddly = [00];
			cmd_edge = [01];
			rdata_edge = [01];
			wdata_edge = [01];
		};
		mmc1@default {
			pins_cmd {
				drive-strength = [06];
			};
			pins_dat {
				drive-strength = [06];
			};
			pins_clk {
				drive-strength = [06];
			};
		};
		mmc1@sdr104 {
			pins_cmd {
				drive-strength = [03];
			};
			pins_dat {
				drive-strength = [03];
			};
			pins_clk {
				drive-strength = [04];
			};
		};
		mmc1@sdr50 {
			pins_cmd {
				drive-strength = [03];
			};
			pins_dat {
				drive-strength = [03];
			};
			pins_clk {
				drive-strength = [04];
			};
		};
		mmc1@ddr50 {
			pins_cmd {
				drive-strength = [03];
			};
			pins_dat {
				drive-strength = [03];
			};
			pins_clk {
				drive-strength = [04];
			};
		};
		mmc1@register_default {
			dat0rddly = [00];
			dat1rddly = [00];
			dat2rddly = [00];
			dat3rddly = [00];
			datwrddly = [00];
			cmdrrddly = [00];
			cmdrddly = [00];
			cmd_edge = [01];
			rdata_edge = [01];
			wdata_edge = [01];
		};
	};
	als_ps@0 {
		interrupt-parent = <&eintc>;
		interrupts = <0x58 0x8>;
		debounce = <0x58 0x0>;
		status = "okay";
		pinctrl-names = "pin_default", "pin_cfg";
		pinctrl-0 = <&nk_alspsdefaultcfg>;
		pinctrl-1 = <&nk_alspspincfg>;
	};
	GSE_1-eint@0 {
		compatible = "mediatek,GSE_1-eint";
		interrupt-parent = <&eintc>;
		interrupts = <0x3e 0x1>;
		debounce = <0x3e 0x0>;
		status = "okay";
	};
	usb_type_c_plat@0 {
		compatible = "mediatek,usb_type_c_plat";
		pinctrl-names = "default", "typec_eint_int";
		pinctrl-0 = <&nk_typec_default1>;
		pinctrl-1 = <&nk_typec_eint_int1>;
		status = "okay";
	};
	usb_type_c@0 {
		compatible = "mediatek,usb_type_c";
	};
	usb_type_eint@0 {
		compatible = "mediatek,usb_type_c_eint";
		interrupt-parent = <&eintc>;
		interrupts = <0x59 0x8>;
		debounce = <0x59 0x0>;
		status = "okay";
	};
	leds@0 {
		compatible = "mediatek,leds";
		pinctrl-names = "default";
		pinctrl-0 = <&nk_eint0default>;
		status = "okay";
	};
	/* nikel: capacitive key backlight (GPIO252, on/off), driver
	 * drivers/leds/leds-nikel-button.c; the pin states moved here from leds@0 */
	button_backlight@0 {
		compatible = "nikel,button-backlight";
		pinctrl-names = "button_backlight_output0", "button_backlight_output1";
		pinctrl-0 = <&nk_button_backlight0>;
		pinctrl-1 = <&nk_button_backlight1>;
		status = "okay";
	};
	hall@0 {
		compatible = "mediatek,hall";
		interrupt-parent = <&eintc>;
		interrupts = <0x5b 0x4>;
		debounce = <0x5b 0x7d00>;
		status = "okay";
		pinctrl-names = "default", "h_eint_int", "h_eint_output0", "h_eint_output1", "h_select_output0", "h_select_output1";
		pinctrl-0 = <&nk_hall_eint0_default>;
		pinctrl-1 = <&nk_hall_eint_0>;
		pinctrl-2 = <&nk_hall_eint_output0>;
		pinctrl-3 = <&nk_hall_eint_output1>;
		pinctrl-4 = <&nk_hall_select_output0>;
		pinctrl-5 = <&nk_hall_select_output1>;
	};
	fast_charger@0 {
		compatible = "mediatek,sw_fast_charger";
		pinctrl-names = "default", "bq_dsel_en_l", "bq_dsel_en_h";
		pinctrl-0 = <&nk_default>;
		pinctrl-1 = <&nk_bq_dsel_en_l>;
		pinctrl-2 = <&nk_bq_dsel_en_h>;
		status = "okay";
	};
	button_touch@0 {
		compatible = "mediatek,button_touch";
	};
	gyroscope@0 {
		interrupt-parent = <&eintc>;
		interrupts = <0x3f 0x4>;
		debounce = <0x3f 0x0>;
		status = "okay";
		pinctrl-names = "pin_default", "pin_cfg";
		pinctrl-0 = <&nk_gyrodefaultcfg>;
		pinctrl-1 = <&nk_gyropincfg>;
	};
	mag_akm09911@0 {
		compatible = "mediatek,mag_akm09911";
		pinctrl-names = "pin_default", "pin_cfg";
		pinctrl-0 = <&nk_magdefaultcfg>;
		pinctrl-1 = <&nk_magpincfg>;
		status = "okay";
	};
	st_step_counter@0 {
		compatible = "mediatek,st_step_counter";
		pinctrl-names = "pin_default", "pin_cfg";
		pinctrl-0 = <&nk_stepdefaultcfg>;
		pinctrl-1 = <&nk_steppincfg>;
		status = "okay";
	};
	deviceinfo {
		compatible = "mediatek,slt_devinfo";
	};
	lcm_params {
		compatible = "mediatek,lcm_params-rm67191_fhd_dsi_vdo";
		lcm_params-types = <0x2 0x0 0x0 0x0>;
		lcm_params-resolution = <0x438 0x780>;
		lcm_params-io_select_mode;
		lcm_params-dbi-port;
		lcm_params-dbi-clock_freq;
		lcm_params-dbi-data_width;
		lcm_params-dbi-data_format;
		lcm_params-dbi-cpu_write_bits;
		lcm_params-dbi-io_driving_current;
		lcm_params-dbi-msb_io_driving_current;
		lcm_params-dbi-ctrl_io_driving_current;
		lcm_params-dbi-te_mode;
		lcm_params-dbi-te_edge_polarity;
		lcm_params-dbi-te_hs_delay_cnt;
		lcm_params-dbi-te_vs_width_cnt;
		lcm_params-dbi-te_vs_width_cnt_div;
		lcm_params-dbi-serial-params0;
		lcm_params-dbi-serial-params1;
		lcm_params-dbi-serial-params2;
		lcm_params-dbi-parallel-params0;
		lcm_params-dbi-parallel-params1;
		lcm_params-dpi-mipi_pll_clk_ref;
		lcm_params-dpi-mipi_pll_clk_div1;
		lcm_params-dpi-mipi_pll_clk_div2;
		lcm_params-dpi-mipi_pll_clk_fbk_div;
		lcm_params-dpi-dpi_clk_div;
		lcm_params-dpi-dpi_clk_duty;
		lcm_params-dpi-PLL_CLOCK;
		lcm_params-dpi-dpi_clock;
		lcm_params-dpi-ssc_disable;
		lcm_params-dpi-ssc_range;
		lcm_params-dpi-width;
		lcm_params-dpi-height;
		lcm_params-dpi-bg_width;
		lcm_params-dpi-bg_height;
		lcm_params-dpi-clk_pol;
		lcm_params-dpi-de_pol;
		lcm_params-dpi-vsync_pol;
		lcm_params-dpi-hsync_pol;
		lcm_params-dpi-hsync_pulse_width;
		lcm_params-dpi-hsync_back_porch;
		lcm_params-dpi-hsync_front_porch;
		lcm_params-dpi-vsync_pulse_width;
		lcm_params-dpi-vsync_back_porch;
		lcm_params-dpi-vsync_front_porch;
		lcm_params-dpi-format;
		lcm_params-dpi-rgb_order;
		lcm_params-dpi-is_serial_output;
		lcm_params-dpi-i2x_en;
		lcm_params-dpi-i2x_edge;
		lcm_params-dpi-embsync;
		lcm_params-dpi-lvds_tx_en;
		lcm_params-dpi-bit_swap;
		lcm_params-dpi-intermediat_buffer_num;
		lcm_params-dpi-io_driving_current;
		lcm_params-dpi-lsb_io_driving_current;
		lcm_params-dsi-mode = <0x3>;
		lcm_params-dsi-switch_mode = <0x1>;
		lcm_params-dsi-DSI_WMEM_CONTI = <0x3c>;
		lcm_params-dsi-DSI_RMEM_CONTI = <0x3e>;
		lcm_params-dsi-VC_NUM;
		lcm_params-dsi-lane_num = <0x4>;
		lcm_params-dsi-data_format = <0x0 0x0 0x0 0x2>;
		lcm_params-dsi-intermediat_buffer_num = <0x2>;
		lcm_params-dsi-ps = <0x2>;
		lcm_params-dsi-word_count;
		lcm_params-dsi-packet_size = <0x100>;
		lcm_params-dsi-vertical_sync_active = <0x2>;
		lcm_params-dsi-vertical_backporch = <0x8>;
		lcm_params-dsi-vertical_frontporch = <0xa>;
		lcm_params-dsi-vertical_frontporch_for_low_power;
		lcm_params-dsi-vertical_active_line = <0x780>;
		lcm_params-dsi-horizontal_sync_active = <0xa>;
		lcm_params-dsi-horizontal_backporch = <0x14>;
		lcm_params-dsi-horizontal_frontporch = <0x28>;
		lcm_params-dsi-horizontal_blanking_pixel;
		lcm_params-dsi-horizontal_active_pixel = <0x438>;
		lcm_params-dsi-horizontal_bllp;
		lcm_params-dsi-line_byte;
		lcm_params-dsi-horizontal_sync_active_byte;
		lcm_params-dsi-horizontal_backportch_byte;
		lcm_params-dsi-horizontal_frontporch_byte;
		lcm_params-dsi-rgb_byte;
		lcm_params-dsi-horizontal_sync_active_word_count;
		lcm_params-dsi-horizontal_backporch_word_count;
		lcm_params-dsi-horizontal_frontporch_word_count;
		lcm_params-dsi-HS_TRAIL;
		lcm_params-dsi-ZERO;
		lcm_params-dsi-HS_PRPR;
		lcm_params-dsi-LPX;
		lcm_params-dsi-TA_SACK;
		lcm_params-dsi-TA_GET;
		lcm_params-dsi-TA_SURE;
		lcm_params-dsi-TA_GO;
		lcm_params-dsi-CLK_TRAIL;
		lcm_params-dsi-CLK_ZERO;
		lcm_params-dsi-LPX_WAIT;
		lcm_params-dsi-CONT_DET;
		lcm_params-dsi-CLK_HS_PRPR;
		lcm_params-dsi-CLK_HS_POST;
		lcm_params-dsi-DA_HS_EXIT;
		lcm_params-dsi-CLK_HS_EXIT;
		lcm_params-dsi-pll_select;
		lcm_params-dsi-pll_div1;
		lcm_params-dsi-pll_div2;
		lcm_params-dsi-fbk_div;
		lcm_params-dsi-fbk_sel;
		lcm_params-dsi-rg_bir;
		lcm_params-dsi-rg_bic;
		lcm_params-dsi-rg_bp;
		lcm_params-dsi-pll_clock = <0x1db>;
		lcm_params-dsi-dsi_clock;
		lcm_params-dsi-ssc_disable = <0x0>;
		lcm_params-dsi-ssc_range = <0x3>;
		lcm_params-dsi-compatibility_for_nvk;
		lcm_params-dsi-cont_clock;
		lcm_params-dsi-ufoe_enable = <0x1>;
		lcm_params-dsi-ufoe_params = <0x0 0x1 0x0 0x0>;
		lcm_params-dsi-edp_panel;
		lcm_params-dsi-customization_esd_check_enable = <0x1>;
		lcm_params-dsi-esd_check_enable = <0x1>;
		lcm_params-dsi-lcm_int_te_monitor;
		lcm_params-dsi-lcm_int_te_period;
		lcm_params-dsi-lcm_ext_te_monitor;
		lcm_params-dsi-lcm_ext_te_enable;
		lcm_params-dsi-noncont_clock;
		lcm_params-dsi-noncont_clock_period;
		lcm_params-dsi-clk_lp_per_line_enable;
		lcm_params-dsi-lcm_esd_check_table0 = <0x53 0x1 0x24 0x0>;
		lcm_params-dsi-lcm_esd_check_table1;
		lcm_params-dsi-lcm_esd_check_table2;
		lcm_params-dsi-switch_mode_enable;
		lcm_params-dsi-dual_dsi_type = <0x1>;
		lcm_params-dsi-lane_swap_en = <0x1>;
		lcm_params-dsi-lane_swap0 = <0x4 0x2 0x1 0x0 0x3 0x3>;
		lcm_params-dsi-lane_swap1 = <0x2 0x4 0x3 0x1 0x0 0x4>;
		lcm_params-dsi-vertical_vfp_lp;
		lcm_params-physical_width;
		lcm_params-physical_height;
		lcm_params-od_table_size;
		lcm_params-od_table;
	};
	lcm_ops {
		compatible = "mediatek,lcm_ops-rm67191_fhd_dsi_vdo";
		init = <0x1 0x1 0x1 0x0 0x1 0x2 0x1 0x1 0x1 0x3 0x1 0x1
			    0x3 0x2 0x1 0x5 0x2 0x1 0x2 0x0 0xe 0x2 0x1 0x2
			    0x1 0xe 0x3 0x1 0x1 0x1 0x3 0x2 0x1 0x1 0x3 0x1
			    0x1 0x0 0x3 0x2 0x1 0xa 0x3 0x1 0x1 0x1 0x3 0x2
			    0x1 0xa 0x4 0x5 0x3 0xff 0x1 0xee 0x4 0x5 0x3 0xfb
			    0x1 0x1 0x4 0x5 0x3 0x18 0x1 0x40 0x3 0x2 0x1 0xa
			    0x4 0x5 0x3 0x18 0x1 0x0 0x3 0x2 0x1 0x14 0x4 0x5
			    0x3 0xff 0x1 0x5 0x4 0x5 0x3 0xc5 0x1 0x31 0x4 0x5
			    0x3 0xfb 0x1 0x1 0x3 0x2 0x1 0x14 0x4 0x5 0x3 0xff
			    0x1 0xee 0x4 0x5 0x3 0x7c 0x1 0x31 0x4 0x5 0x3 0xfb
			    0x1 0x1 0x4 0x5 0x3 0xff 0x1 0x1 0x4 0x5 0x3 0x0
			    0x1 0x1 0x4 0x5 0x3 0x1 0x1 0x55 0x4 0x5 0x3 0x2
			    0x1 0x40 0x4 0x5 0x3 0x5 0x1 0x50 0x4 0x5 0x3 0x6
			    0x1 0x4a 0x4 0x5 0x3 0x7 0x1 0x29 0x4 0x5 0x3 0x8
			    0x1 0xc 0x4 0x5 0x3 0xb 0x1 0x9b 0x4 0x5 0x3 0xc
			    0x1 0x9b 0x4 0x5 0x3 0xe 0x1 0xb0 0x4 0x5 0x3 0xf
			    0x1 0xb3 0x4 0x5 0x3 0x11 0x1 0x10 0x4 0x5 0x3 0x12
			    0x1 0x10 0x4 0x5 0x3 0x13 0x1 0x3 0x4 0x5 0x3 0x14
			    0x1 0x4a 0x4 0x5 0x3 0x15 0x1 0x12 0x4 0x5 0x3 0x16
			    0x1 0x12 0x4 0x5 0x3 0x18 0x1 0x0 0x4 0x5 0x3 0x19
			    0x1 0x77 0x4 0x5 0x3 0x1a 0x1 0x55 0x4 0x5 0x3 0x1b
			    0x1 0x13 0x4 0x5 0x3 0x1c 0x1 0x0 0x4 0x5 0x3 0x1d
			    0x1 0x0 0x4 0x5 0x3 0x1e 0x1 0x0 0x4 0x5 0x3 0x1f
			    0x1 0x0 0x4 0x5 0x3 0x58 0x1 0x82 0x4 0x5 0x3 0x59
			    0x1 0x2 0x4 0x5 0x3 0x5a 0x1 0x2 0x4 0x5 0x3 0x5b
			    0x1 0x2 0x4 0x5 0x3 0x5c 0x1 0x82 0x4 0x5 0x3 0x5d
			    0x1 0x82 0x4 0x5 0x3 0x5e 0x1 0x2 0x4 0x5 0x3 0x5f
			    0x1 0x2 0x4 0x5 0x3 0x72 0x1 0x31 0x4 0x5 0x3 0xfb
			    0x1 0x1 0x4 0x5 0x3 0xff 0x1 0x5 0x4 0x5 0x3 0x0
			    0x1 0x1 0x4 0x5 0x3 0x1 0x1 0xb 0x4 0x5 0x3 0x2
			    0x1 0xc 0x4 0x5 0x3 0x3 0x1 0x9 0x4 0x5 0x3 0x4
			    0x1 0xa 0x4 0x5 0x3 0x5 0x1 0xf 0x4 0x5 0x3 0x6
			    0x1 0x10 0x4 0x5 0x3 0x7 0x1 0x0 0x4 0x5 0x3 0x8
			    0x1 0x1a 0x4 0x5 0x3 0x9 0x1 0x0 0x4 0x5 0x3 0xa
			    0x1 0x0 0x4 0x5 0x3 0xb 0x1 0x0 0x4 0x5 0x3 0xc
			    0x1 0x0 0x4 0x5 0x3 0xd 0x1 0x13 0x4 0x5 0x3 0xe
			    0x1 0x15 0x4 0x5 0x3 0xf 0x1 0x17 0x4 0x5 0x3 0x10
			    0x1 0x1 0x4 0x5 0x3 0x11 0x1 0xb 0x4 0x5 0x3 0x12
			    0x1 0xc 0x4 0x5 0x3 0x13 0x1 0x9 0x4 0x5 0x3 0x14
			    0x1 0xa 0x4 0x5 0x3 0x15 0x1 0xf 0x4 0x5 0x3 0x16
			    0x1 0x10 0x4 0x5 0x3 0x17 0x1 0x10 0x4 0x5 0x3 0x18
			    0x1 0x1a 0x4 0x5 0x3 0x19 0x1 0x0 0x4 0x5 0x3 0x1a
			    0x1 0x0 0x4 0x5 0x3 0x1b 0x1 0x0 0x4 0x5 0x3 0x1c
			    0x1 0x0 0x4 0x5 0x3 0x1d 0x1 0x13 0x4 0x5 0x3 0x1e
			    0x1 0x15 0x4 0x5 0x3 0x1f 0x1 0x17 0x4 0x5 0x3 0x20
			    0x1 0x0 0x4 0x5 0x3 0x21 0x1 0x1 0x4 0x5 0x3 0x22
			    0x1 0x0 0x4 0x5 0x3 0x23 0x1 0x36 0x4 0x5 0x3 0x24
			    0x1 0x36 0x4 0x5 0x3 0x25 0x1 0x6d 0x4 0x5 0x3 0x29
			    0x1 0xd8 0x4 0x5 0x3 0x2a 0x1 0x2a 0x4 0x5 0x3 0x2b
			    0x1 0x0 0x4 0x5 0x3 0xb6 0x1 0x89 0x4 0x5 0x3 0xb7
			    0x1 0x14 0x4 0x5 0x3 0xb8 0x1 0x5 0x4 0x5 0x3 0x4b
			    0x1 0x4 0x4 0x5 0x3 0x4c 0x1 0x11 0x4 0x5 0x3 0x4d
			    0x1 0x0 0x4 0x5 0x3 0x4e 0x1 0x0 0x4 0x5 0x3 0x4f
			    0x1 0x11 0x4 0x5 0x3 0x50 0x1 0x11 0x4 0x5 0x3 0x51
			    0x1 0x0 0x4 0x5 0x3 0x52 0x1 0x0 0x4 0x5 0x3 0x53
			    0x1 0x1 0x4 0x5 0x3 0x54 0x1 0x75 0x4 0x5 0x3 0x55
			    0x1 0x6d 0x4 0x5 0x3 0x5b 0x1 0x44 0x4 0x5 0x3 0x5c
			    0x1 0x0 0x4 0x5 0x3 0x5f 0x1 0x74 0x4 0x5 0x3 0x60
			    0x1 0x75 0x4 0x5 0x3 0x63 0x1 0xff 0x4 0x5 0x3 0x64
			    0x1 0x0 0x4 0x5 0x3 0x67 0x1 0x4 0x4 0x5 0x3 0x68
			    0x1 0x4 0x4 0x5 0x3 0x6c 0x1 0x0 0x4 0x5 0x3 0x7a
			    0x1 0x80 0x4 0x5 0x3 0x7b 0x1 0x91 0x4 0x5 0x3 0x7c
			    0x1 0xd8 0x4 0x5 0x3 0x7d 0x1 0x60 0x4 0x5 0x3 0x7e
			    0x1 0xa 0x4 0x5 0x3 0x7f 0x1 0x1a 0x4 0x5 0x3 0x80
			    0x1 0x0 0x4 0x5 0x3 0x83 0x1 0x0 0x4 0x5 0x3 0x93
			    0x1 0x8 0x4 0x5 0x3 0x94 0x1 0xa 0x4 0x5 0x3 0x8a
			    0x1 0x33 0x4 0x5 0x3 0x9b 0x1 0xf 0x4 0x5 0x3 0xa4
			    0x1 0xf 0x4 0x5 0x3 0xe7 0x1 0x80 0x4 0x5 0x3 0xfb
			    0x1 0x1 0x4 0x5 0x3 0xff 0x1 0x1 0x4 0x5 0x3 0xfb
			    0x1 0x1 0x4 0x5 0x3 0x75 0x1 0x0 0x4 0x5 0x3 0x76
			    0x1 0x0 0x4 0x5 0x3 0x77 0x1 0x0 0x4 0x5 0x3 0x78
			    0x1 0x4f 0x4 0x5 0x3 0x79 0x1 0x0 0x4 0x5 0x3 0x7a
			    0x1 0x88 0x4 0x5 0x3 0x7b 0x1 0x0 0x4 0x5 0x3 0x7c
			    0x1 0xaa 0x4 0x5 0x3 0x7d 0x1 0x0 0x4 0x5 0x3 0x7e
			    0x1 0xc4 0x4 0x5 0x3 0x7f 0x1 0x0 0x4 0x5 0x3 0x80
			    0x1 0xd9 0x4 0x5 0x3 0x81 0x1 0x0 0x4 0x5 0x3 0x82
			    0x1 0xeb 0x4 0x5 0x3 0x83 0x1 0x0 0x4 0x5 0x3 0x84
			    0x1 0xfc 0x4 0x5 0x3 0x85 0x1 0x1 0x4 0x5 0x3 0x86
			    0x1 0xa 0x4 0x5 0x3 0x87 0x1 0x1 0x4 0x5 0x3 0x88
			    0x1 0x3a 0x4 0x5 0x3 0x89 0x1 0x1 0x4 0x5 0x3 0x8a
			    0x1 0x60 0x4 0x5 0x3 0x8b 0x1 0x1 0x4 0x5 0x3 0x8c
			    0x1 0x99 0x4 0x5 0x3 0x8d 0x1 0x1 0x4 0x5 0x3 0x8e
			    0x1 0xc6 0x4 0x5 0x3 0x8f 0x1 0x2 0x4 0x5 0x3 0x90
			    0x1 0xa 0x4 0x5 0x3 0x91 0x1 0x2 0x4 0x5 0x3 0x92
			    0x1 0x40 0x4 0x5 0x3 0x93 0x1 0x2 0x4 0x5 0x3 0x94
			    0x1 0x41 0x4 0x5 0x3 0x95 0x1 0x2 0x4 0x5 0x3 0x96
			    0x1 0x71 0x4 0x5 0x3 0x97 0x1 0x2 0x4 0x5 0x3 0x98
			    0x1 0xa5 0x4 0x5 0x3 0x99 0x1 0x2 0x4 0x5 0x3 0x9a
			    0x1 0xc7 0x4 0x5 0x3 0x9b 0x1 0x2 0x4 0x5 0x3 0x9c
			    0x1 0xf6 0x4 0x5 0x3 0x9d 0x1 0x3 0x4 0x5 0x3 0x9e
			    0x1 0x17 0x4 0x5 0x3 0x9f 0x1 0x3 0x4 0x5 0x3 0xa0
			    0x1 0x3f 0x4 0x5 0x3 0xa2 0x1 0x3 0x4 0x5 0x3 0xa3
			    0x1 0x4c 0x4 0x5 0x3 0xa4 0x1 0x3 0x4 0x5 0x3 0xa5
			    0x1 0x5a 0x4 0x5 0x3 0xa6 0x1 0x3 0x4 0x5 0x3 0xa7
			    0x1 0x68 0x4 0x5 0x3 0xa9 0x1 0x3 0x4 0x5 0x3 0xaa
			    0x1 0x78 0x4 0x5 0x3 0xab 0x1 0x3 0x4 0x5 0x3 0xac
			    0x1 0x8a 0x4 0x5 0x3 0xad 0x1 0x3 0x4 0x5 0x3 0xae
			    0x1 0x9f 0x4 0x5 0x3 0xaf 0x1 0x3 0x4 0x5 0x3 0xb0
			    0x1 0xf4 0x4 0x5 0x3 0xb1 0x1 0x3 0x4 0x5 0x3 0xb2
			    0x1 0xfe 0x4 0x5 0x3 0xb3 0x1 0x0 0x4 0x5 0x3 0xb4
			    0x1 0x0 0x4 0x5 0x3 0xb5 0x1 0x0 0x4 0x5 0x3 0xb6
			    0x1 0x4f 0x4 0x5 0x3 0xb7 0x1 0x0 0x4 0x5 0x3 0xb8
			    0x1 0x88 0x4 0x5 0x3 0xb9 0x1 0x0 0x4 0x5 0x3 0xba
			    0x1 0xaa 0x4 0x5 0x3 0xbb 0x1 0x0 0x4 0x5 0x3 0xbc
			    0x1 0xc4 0x4 0x5 0x3 0xbd 0x1 0x0 0x4 0x5 0x3 0xbe
			    0x1 0xd9 0x4 0x5 0x3 0xbf 0x1 0x0 0x4 0x5 0x3 0xc0
			    0x1 0xeb 0x4 0x5 0x3 0xc1 0x1 0x0 0x4 0x5 0x3 0xc2
			    0x1 0xfc 0x4 0x5 0x3 0xc3 0x1 0x1 0x4 0x5 0x3 0xc4
			    0x1 0xa 0x4 0x5 0x3 0xc5 0x1 0x1 0x4 0x5 0x3 0xc6
			    0x1 0x3a 0x4 0x5 0x3 0xc7 0x1 0x1 0x4 0x5 0x3 0xc8
			    0x1 0x60 0x4 0x5 0x3 0xc9 0x1 0x1 0x4 0x5 0x3 0xca
			    0x1 0x99 0x4 0x5 0x3 0xcb 0x1 0x1 0x4 0x5 0x3 0xcc
			    0x1 0xc6 0x4 0x5 0x3 0xcd 0x1 0x2 0x4 0x5 0x3 0xce
			    0x1 0xa 0x4 0x5 0x3 0xcf 0x1 0x2 0x4 0x5 0x3 0xd0
			    0x1 0x40 0x4 0x5 0x3 0xd1 0x1 0x2 0x4 0x5 0x3 0xd2
			    0x1 0x41 0x4 0x5 0x3 0xd3 0x1 0x2 0x4 0x5 0x3 0xd4
			    0x1 0x71 0x4 0x5 0x3 0xd5 0x1 0x2 0x4 0x5 0x3 0xd6
			    0x1 0xa5 0x4 0x5 0x3 0xd7 0x1 0x2 0x4 0x5 0x3 0xd8
			    0x1 0xc7 0x4 0x5 0x3 0xd9 0x1 0x2 0x4 0x5 0x3 0xda
			    0x1 0xf6 0x4 0x5 0x3 0xdb 0x1 0x3 0x4 0x5 0x3 0xdc
			    0x1 0x17 0x4 0x5 0x3 0xdd 0x1 0x3 0x4 0x5 0x3 0xde
			    0x1 0x3f 0x4 0x5 0x3 0xdf 0x1 0x3 0x4 0x5 0x3 0xe0
			    0x1 0x4c 0x4 0x5 0x3 0xe1 0x1 0x3 0x4 0x5 0x3 0xe2
			    0x1 0x5a 0x4 0x5 0x3 0xe3 0x1 0x3 0x4 0x5 0x3 0xe4
			    0x1 0x68 0x4 0x5 0x3 0xe5 0x1 0x3 0x4 0x5 0x3 0xe6
			    0x1 0x78 0x4 0x5 0x3 0xe7 0x1 0x3 0x4 0x5 0x3 0xe8
			    0x1 0x8a 0x4 0x5 0x3 0xe9 0x1 0x3 0x4 0x5 0x3 0xea
			    0x1 0x9f 0x4 0x5 0x3 0xeb 0x1 0x3 0x4 0x5 0x3 0xec
			    0x1 0xf4 0x4 0x5 0x3 0xed 0x1 0x3 0x4 0x5 0x3 0xee
			    0x1 0xfe 0x4 0x5 0x3 0xef 0x1 0x0 0x4 0x5 0x3 0xf0
			    0x1 0x0 0x4 0x5 0x3 0xf1 0x1 0x0 0x4 0x5 0x3 0xf2
			    0x1 0x4f 0x4 0x5 0x3 0xf3 0x1 0x0 0x4 0x5 0x3 0xf4
			    0x1 0x88 0x4 0x5 0x3 0xf5 0x1 0x0 0x4 0x5 0x3 0xf6
			    0x1 0xaa 0x4 0x5 0x3 0xf7 0x1 0x0 0x4 0x5 0x3 0xf8
			    0x1 0xc4 0x4 0x5 0x3 0xf9 0x1 0x0 0x4 0x5 0x3 0xfa
			    0x1 0xd9 0x4 0x5 0x3 0xff 0x1 0x2 0x4 0x5 0x3 0xfb
			    0x1 0x1 0x4 0x5 0x3 0x0 0x1 0x0 0x4 0x5 0x3 0x1
			    0x1 0xeb 0x4 0x5 0x3 0x2 0x1 0x0 0x4 0x5 0x3 0x3
			    0x1 0xfc 0x4 0x5 0x3 0x4 0x1 0x1 0x4 0x5 0x3 0x5
			    0x1 0xa 0x4 0x5 0x3 0x6 0x1 0x1 0x4 0x5 0x3 0x7
			    0x1 0x3a 0x4 0x5 0x3 0x8 0x1 0x1 0x4 0x5 0x3 0x9
			    0x1 0x60 0x4 0x5 0x3 0xa 0x1 0x1 0x4 0x5 0x3 0xb
			    0x1 0x99 0x4 0x5 0x3 0xc 0x1 0x1 0x4 0x5 0x3 0xd
			    0x1 0xc6 0x4 0x5 0x3 0xe 0x1 0x2 0x4 0x5 0x3 0xf
			    0x1 0xa 0x4 0x5 0x3 0x10 0x1 0x2 0x4 0x5 0x3 0x11
			    0x1 0x40 0x4 0x5 0x3 0x12 0x1 0x2 0x4 0x5 0x3 0x13
			    0x1 0x41 0x4 0x5 0x3 0x14 0x1 0x2 0x4 0x5 0x3 0x15
			    0x1 0x71 0x4 0x5 0x3 0x16 0x1 0x2 0x4 0x5 0x3 0x17
			    0x1 0xa5 0x4 0x5 0x3 0x18 0x1 0x2 0x4 0x5 0x3 0x19
			    0x1 0xc7 0x4 0x5 0x3 0x1a 0x1 0x2 0x4 0x5 0x3 0x1b
			    0x1 0xf6 0x4 0x5 0x3 0x1c 0x1 0x3 0x4 0x5 0x3 0x1d
			    0x1 0x17 0x4 0x5 0x3 0x1e 0x1 0x3 0x4 0x5 0x3 0x1f
			    0x1 0x3f 0x4 0x5 0x3 0x20 0x1 0x3 0x4 0x5 0x3 0x21
			    0x1 0x4c 0x4 0x5 0x3 0x22 0x1 0x3 0x4 0x5 0x3 0x23
			    0x1 0x5a 0x4 0x5 0x3 0x24 0x1 0x3 0x4 0x5 0x3 0x25
			    0x1 0x68 0x4 0x5 0x3 0x26 0x1 0x3 0x4 0x5 0x3 0x27
			    0x1 0x78 0x4 0x5 0x3 0x28 0x1 0x3 0x4 0x5 0x3 0x29
			    0x1 0x8a 0x4 0x5 0x3 0x2a 0x1 0x3 0x4 0x5 0x3 0x2b
			    0x1 0x9f 0x4 0x5 0x3 0x2d 0x1 0x3 0x4 0x5 0x3 0x2f
			    0x1 0xf4 0x4 0x5 0x3 0x30 0x1 0x3 0x4 0x5 0x3 0x31
			    0x1 0xfe 0x4 0x5 0x3 0x32 0x1 0x0 0x4 0x5 0x3 0x33
			    0x1 0x0 0x4 0x5 0x3 0x34 0x1 0x0 0x4 0x5 0x3 0x35
			    0x1 0x4f 0x4 0x5 0x3 0x36 0x1 0x0 0x4 0x5 0x3 0x37
			    0x1 0x88 0x4 0x5 0x3 0x38 0x1 0x0 0x4 0x5 0x3 0x39
			    0x1 0xaa 0x4 0x5 0x3 0x3a 0x1 0x0 0x4 0x5 0x3 0x3b
			    0x1 0xc4 0x4 0x5 0x3 0x3d 0x1 0x0 0x4 0x5 0x3 0x3f
			    0x1 0xd9 0x4 0x5 0x3 0x40 0x1 0x0 0x4 0x5 0x3 0x41
			    0x1 0xeb 0x4 0x5 0x3 0x42 0x1 0x0 0x4 0x5 0x3 0x43
			    0x1 0xfc 0x4 0x5 0x3 0x44 0x1 0x1 0x4 0x5 0x3 0x45
			    0x1 0xa 0x4 0x5 0x3 0x46 0x1 0x1 0x4 0x5 0x3 0x47
			    0x1 0x3a 0x4 0x5 0x3 0x48 0x1 0x1 0x4 0x5 0x3 0x49
			    0x1 0x60 0x4 0x5 0x3 0x4a 0x1 0x1 0x4 0x5 0x3 0x4b
			    0x1 0x99 0x4 0x5 0x3 0x4c 0x1 0x1 0x4 0x5 0x3 0x4d
			    0x1 0xc6 0x4 0x5 0x3 0x4e 0x1 0x2 0x4 0x5 0x3 0x4f
			    0x1 0xa 0x4 0x5 0x3 0x50 0x1 0x2 0x4 0x5 0x3 0x51
			    0x1 0x40 0x4 0x5 0x3 0x52 0x1 0x2 0x4 0x5 0x3 0x53
			    0x1 0x41 0x4 0x5 0x3 0x54 0x1 0x2 0x4 0x5 0x3 0x55
			    0x1 0x71 0x4 0x5 0x3 0x56 0x1 0x2 0x4 0x5 0x3 0x58
			    0x1 0xa5 0x4 0x5 0x3 0x59 0x1 0x2 0x4 0x5 0x3 0x5a
			    0x1 0xc7 0x4 0x5 0x3 0x5b 0x1 0x2 0x4 0x5 0x3 0x5c
			    0x1 0xf6 0x4 0x5 0x3 0x5d 0x1 0x3 0x4 0x5 0x3 0x5e
			    0x1 0x17 0x4 0x5 0x3 0x5f 0x1 0x3 0x4 0x5 0x3 0x60
			    0x1 0x3f 0x4 0x5 0x3 0x61 0x1 0x3 0x4 0x5 0x3 0x62
			    0x1 0x4c 0x4 0x5 0x3 0x63 0x1 0x3 0x4 0x5 0x3 0x64
			    0x1 0x5a 0x4 0x5 0x3 0x65 0x1 0x3 0x4 0x5 0x3 0x66
			    0x1 0x68 0x4 0x5 0x3 0x67 0x1 0x3 0x4 0x5 0x3 0x68
			    0x1 0x78 0x4 0x5 0x3 0x69 0x1 0x3 0x4 0x5 0x3 0x6a
			    0x1 0x8a 0x4 0x5 0x3 0x6b 0x1 0x3 0x4 0x5 0x3 0x6c
			    0x1 0x9f 0x4 0x5 0x3 0x6d 0x1 0x3 0x4 0x5 0x3 0x6e
			    0x1 0xf4 0x4 0x5 0x3 0x6f 0x1 0x3 0x4 0x5 0x3 0x70
			    0x1 0xfe 0x4 0x5 0x3 0x71 0x1 0x0 0x4 0x5 0x3 0x72
			    0x1 0x0 0x4 0x5 0x3 0x73 0x1 0x0 0x4 0x5 0x3 0x74
			    0x1 0x4f 0x4 0x5 0x3 0x75 0x1 0x0 0x4 0x5 0x3 0x76
			    0x1 0x88 0x4 0x5 0x3 0x77 0x1 0x0 0x4 0x5 0x3 0x78
			    0x1 0xaa 0x4 0x5 0x3 0x79 0x1 0x0 0x4 0x5 0x3 0x7a
			    0x1 0xc4 0x4 0x5 0x3 0x7b 0x1 0x0 0x4 0x5 0x3 0x7c
			    0x1 0xd9 0x4 0x5 0x3 0x7d 0x1 0x0 0x4 0x5 0x3 0x7e
			    0x1 0xeb 0x4 0x5 0x3 0x7f 0x1 0x0 0x4 0x5 0x3 0x80
			    0x1 0xfc 0x4 0x5 0x3 0x81 0x1 0x1 0x4 0x5 0x3 0x82
			    0x1 0xa 0x4 0x5 0x3 0x83 0x1 0x1 0x4 0x5 0x3 0x84
			    0x1 0x3a 0x4 0x5 0x3 0x85 0x1 0x1 0x4 0x5 0x3 0x86
			    0x1 0x60 0x4 0x5 0x3 0x87 0x1 0x1 0x4 0x5 0x3 0x88
			    0x1 0x99 0x4 0x5 0x3 0x89 0x1 0x1 0x4 0x5 0x3 0x8a
			    0x1 0xc6 0x4 0x5 0x3 0x8b 0x1 0x2 0x4 0x5 0x3 0x8c
			    0x1 0xa 0x4 0x5 0x3 0x8d 0x1 0x2 0x4 0x5 0x3 0x8e
			    0x1 0x40 0x4 0x5 0x3 0x8f 0x1 0x2 0x4 0x5 0x3 0x90
			    0x1 0x41 0x4 0x5 0x3 0x91 0x1 0x2 0x4 0x5 0x3 0x92
			    0x1 0x71 0x4 0x5 0x3 0x93 0x1 0x2 0x4 0x5 0x3 0x94
			    0x1 0xa5 0x4 0x5 0x3 0x95 0x1 0x2 0x4 0x5 0x3 0x96
			    0x1 0xc7 0x4 0x5 0x3 0x97 0x1 0x2 0x4 0x5 0x3 0x98
			    0x1 0xf6 0x4 0x5 0x3 0x99 0x1 0x3 0x4 0x5 0x3 0x9a
			    0x1 0x17 0x4 0x5 0x3 0x9b 0x1 0x3 0x4 0x5 0x3 0x9c
			    0x1 0x3f 0x4 0x5 0x3 0x9d 0x1 0x3 0x4 0x5 0x3 0x9e
			    0x1 0x4c 0x4 0x5 0x3 0x9f 0x1 0x3 0x4 0x5 0x3 0xa0
			    0x1 0x5a 0x4 0x5 0x3 0xa2 0x1 0x3 0x4 0x5 0x3 0xa3
			    0x1 0x68 0x4 0x5 0x3 0xa4 0x1 0x3 0x4 0x5 0x3 0xa5
			    0x1 0x78 0x4 0x5 0x3 0xa6 0x1 0x3 0x4 0x5 0x3 0xa7
			    0x1 0x8a 0x4 0x5 0x3 0xa9 0x1 0x3 0x4 0x5 0x3 0xaa
			    0x1 0x9f 0x4 0x5 0x3 0xab 0x1 0x3 0x4 0x5 0x3 0xac
			    0x1 0xf4 0x4 0x5 0x3 0xad 0x1 0x3 0x4 0x5 0x3 0xae
			    0x1 0xfe 0x4 0x5 0x3 0xaf 0x1 0x0 0x4 0x5 0x3 0xb0
			    0x1 0x0 0x4 0x5 0x3 0xb1 0x1 0x0 0x4 0x5 0x3 0xb2
			    0x1 0x4f 0x4 0x5 0x3 0xb3 0x1 0x0 0x4 0x5 0x3 0xb4
			    0x1 0x88 0x4 0x5 0x3 0xb5 0x1 0x0 0x4 0x5 0x3 0xb6
			    0x1 0xaa 0x4 0x5 0x3 0xb7 0x1 0x0 0x4 0x5 0x3 0xb8
			    0x1 0xc4 0x4 0x5 0x3 0xb9 0x1 0x0 0x4 0x5 0x3 0xba
			    0x1 0xd9 0x4 0x5 0x3 0xbb 0x1 0x0 0x4 0x5 0x3 0xbc
			    0x1 0xeb 0x4 0x5 0x3 0xbd 0x1 0x0 0x4 0x5 0x3 0xbe
			    0x1 0xfc 0x4 0x5 0x3 0xbf 0x1 0x1 0x4 0x5 0x3 0xc0
			    0x1 0xa 0x4 0x5 0x3 0xc1 0x1 0x1 0x4 0x5 0x3 0xc2
			    0x1 0x3a 0x4 0x5 0x3 0xc3 0x1 0x1 0x4 0x5 0x3 0xc4
			    0x1 0x60 0x4 0x5 0x3 0xc5 0x1 0x1 0x4 0x5 0x3 0xc6
			    0x1 0x99 0x4 0x5 0x3 0xc7 0x1 0x1 0x4 0x5 0x3 0xc8
			    0x1 0xc6 0x4 0x5 0x3 0xc9 0x1 0x2 0x4 0x5 0x3 0xca
			    0x1 0xa 0x4 0x5 0x3 0xcb 0x1 0x2 0x4 0x5 0x3 0xcc
			    0x1 0x40 0x4 0x5 0x3 0xcd 0x1 0x2 0x4 0x5 0x3 0xce
			    0x1 0x41 0x4 0x5 0x3 0xcf 0x1 0x2 0x4 0x5 0x3 0xd0
			    0x1 0x71 0x4 0x5 0x3 0xd1 0x1 0x2 0x4 0x5 0x3 0xd2
			    0x1 0xa5 0x4 0x5 0x3 0xd3 0x1 0x2 0x4 0x5 0x3 0xd4
			    0x1 0xc7 0x4 0x5 0x3 0xd5 0x1 0x2 0x4 0x5 0x3 0xd6
			    0x1 0xf6 0x4 0x5 0x3 0xd7 0x1 0x3 0x4 0x5 0x3 0xd8
			    0x1 0x17 0x4 0x5 0x3 0xd9 0x1 0x3 0x4 0x5 0x3 0xda
			    0x1 0x3f 0x4 0x5 0x3 0xdb 0x1 0x3 0x4 0x5 0x3 0xdc
			    0x1 0x4c 0x4 0x5 0x3 0xdd 0x1 0x3 0x4 0x5 0x3 0xde
			    0x1 0x5a 0x4 0x5 0x3 0xdf 0x1 0x3 0x4 0x5 0x3 0xe0
			    0x1 0x68 0x4 0x5 0x3 0xe1 0x1 0x3 0x4 0x5 0x3 0xe2
			    0x1 0x78 0x4 0x5 0x3 0xe3 0x1 0x3 0x4 0x5 0x3 0xe4
			    0x1 0x8a 0x4 0x5 0x3 0xe5 0x1 0x3 0x4 0x5 0x3 0xe6
			    0x1 0x9f 0x4 0x5 0x3 0xe7 0x1 0x3 0x4 0x5 0x3 0xe8
			    0x1 0xf4 0x4 0x5 0x3 0xe9 0x1 0x3 0x4 0x5 0x3 0xea
			    0x1 0xfe 0x4 0x5 0x3 0xff 0x1 0x0 0x4 0x5 0x3 0xfb
			    0x1 0x1 0x4 0x5 0x3 0xd3 0x1 0x6 0x4 0x5 0x3 0xd4
			    0x1 0x4 0x4 0x5 0x3 0x35 0x1 0x0 0x4 0x5 0x3 0x51
			    0x1 0x7f 0x4 0x5 0x3 0x53 0x1 0x2c 0x4 0x5 0x3 0x55
			    0x1 0x0 0x4 0x5 0x2 0x29 0x0 0x3 0x2 0x1 0x14 0x4
			    0x5 0x2 0x11 0x0 0x3 0x2 0x1 0x78>;
		compare_id = <0x3 0x1 0x1 0x1 0x3 0x2 0x1 0xa 0x3 0x1 0x1 0x0
			    0x3 0x2 0x1 0xa 0x3 0x1 0x1 0x1 0x3 0x2 0x1 0xa
			    0x4 0x4 0x5 0x1 0x0 0x37 0x3 0x0 0x4 0x7 0x3 0xf4
			    0x1 0x95>;
		suspend = <0x4 0x5 0x2 0x28 0x0 0x3 0x2 0x1 0x14 0x4 0x5 0x2
			    0x10 0x0 0x3 0x2 0x1 0x78 0x1 0x1 0x1 0x0 0x1 0x2
			    0x1 0x1 0x1 0x3 0x1 0x0>;
		backlight = <0x4 0x5 0x3 0x51 0x1 0xff 0x4 0x5 0x3 0x53 0x1 0x24
			    0x4 0x5 0x3 0x55 0x1 0x1>;
	};
	led@0 {
		compatible = "mediatek,red";
		led_mode = <0x3>;
		data = <0x2>;
		pwm_config = <0x0 0x0 0x0 0x0 0x0>;
	};
	led@1 {
		compatible = "mediatek,green";
		led_mode = <0x3>;
		data = <0x4>;
		pwm_config = <0x0 0x0 0x0 0x0 0x0>;
	};
	led@2 {
		compatible = "mediatek,blue";
		led_mode = <0x3>;
		data = <0x3>;
		pwm_config = <0x0 0x0 0x0 0x0 0x0>;
	};
	led@3 {
		compatible = "mediatek,jogball-backlight";
		led_mode = <0x0>;
		data = <0x1>;
		pwm_config = <0x0 0x0 0x0 0x0 0x0>;
	};
	led@4 {
		compatible = "mediatek,keyboard-backlight";
		led_mode = <0x0>;
		data = <0x1>;
		pwm_config = <0x0 0x0 0x0 0x0 0x0>;
	};
	led@5 {
		compatible = "mediatek,button-backlight";
		/*
		 * nikel stock: mode 2 (GPIO) with data = 1. In SHIFT's LED driver,
		 * GPIO mode calls "data" as a function -> jump to address 0x1, kernel
		 * panic as soon as TWRP lit the key backlight (test boot #2). Xiaomi
		 * drove the key backlight with custom code (button_backlight0/1 pin
		 * states). Off until a small GPIO handler is ported.
		 */
		led_mode = <0x0>;
		data = <0x1>;
		pwm_config = <0x0 0x0 0x0 0x0 0x0>;
	};
	led@6 {
		compatible = "mediatek,lcd-backlight";
		led_mode = <0x4>;
		data = <0x0>;
		pwm_config = <0x0 0x0 0x0 0x0 0x0>;
	};
	led@7 {
		compatible = "mediatek,flashlight";
		led_mode = <0x6>;
		data = <0x0>;
		pwm_config = <0x0 0x0 0x0 0x0 0x0>;
	};
	led@8 {
		compatible = "mediatek,yellow";
		led_mode = <0x3>;
		data = <0x4>;
		pwm_config = <0x0 0x0 0x0 0x0 0x0>;
	};
	led@9 {
		compatible = "mediatek,white";
		led_mode = <0x3>;
		data = <0x4>;
		pwm_config = <0x0 0x0 0x0 0x0 0x0>;
	};
	led@10 {
		compatible = "mediatek,cyan";
		led_mode = <0x3>;
		data = <0x4>;
		pwm_config = <0x0 0x0 0x0 0x0 0x0>;
	};
	led@11 {
		compatible = "mediatek,violet";
		led_mode = <0x3>;
		data = <0x4>;
		pwm_config = <0x0 0x0 0x0 0x0 0x0>;
	};
	vibrator@0 {
		compatible = "mediatek,vibrator";
		vib_timer = <0x19>;
		vib_limit = <0x9>;
		vib_vol = <0x5>;
	};
	cust_accel@0 {
		compatible = "mediatek,bmi160_acc";
		i2c_num = <0x1>;
		i2c_addr = <0x68 0x0 0x0 0x0>;
		direction = <0x3>;
		power_id = <0xffff>;
		power_vol = <0x0>;
		firlen = <0x0>;
		is_batch_supported = <0x0>;
	};
	cust_accel@1 {
		compatible = "mediatek,lsm6ds3_acc";
		i2c_num = <0x1>;
		i2c_addr = <0x6a 0x0 0x0 0x0>;
		direction = <0x2>;
		power_id = <0xffff>;
		power_vol = <0x0>;
		firlen = <0x0>;
		is_batch_supported = <0x0>;
	};
	cust_alsps@0 {
		compatible = "mediatek,ltr579-new";
		i2c_num = <0x1>;
		i2c_addr = <0x53 0x0 0x0 0x0>;
		polling_mode_ps = <0x0>;
		polling_mode_als = <0x1>;
		power_id = <0xffff>;
		power_vol = <0x0>;
		als_level = <0x1 0x4 0xa 0x1e 0x78 0x96 0xff 0x17c 0x28a 0x384 0x546 0x898
			    0xdac 0x1770 0x2710 0x4e20 0x7530 0xc350>;
		als_value = <0x0 0x5 0xa 0x1e 0x50 0x78 0xe1 0x140 0x226 0x320 0x4e2 0x7d0
			    0xbb8 0x1388 0x157c 0x1d4c 0x32c8 0x5dc0 0x7530>;
		ps_threshold_high = <0x3c>;
		ps_threshold_low = <0x28>;
		is_batch_supported_ps = <0x0>;
		is_batch_supported_als = <0x0>;
	};
	cust_alsps@1 {
		compatible = "mediatek,apds9922";
		i2c_num = <0x1>;
		i2c_addr = <0x53 0x0 0x0 0x0>;
		polling_mode_ps = <0x0>;
		polling_mode_als = <0x1>;
		power_id = <0xffff>;
		power_vol = <0x0>;
		als_level = <0x1 0x4 0xa 0x1e 0x78 0x96 0xff 0x17c 0x28a 0x384 0x546 0x898
			    0xdac 0x1770 0x2710 0x4e20 0x7530 0xc350>;
		als_value = <0x0 0x5 0xa 0x1e 0x50 0x78 0xe1 0x140 0x226 0x320 0x4e2 0x7d0
			    0xbb8 0x1388 0x157c 0x1d4c 0x32c8 0x5dc0 0x7530>;
		ps_threshold_high = <0x3c>;
		ps_threshold_low = <0x28>;
		is_batch_supported_ps = <0x0>;
		is_batch_supported_als = <0x0>;
	};
	cust_mag@0 {
		compatible = "mediatek,yamaha537";
		i2c_num = <0x1>;
		i2c_addr = <0x2e 0x0 0x0 0x0>;
		direction = <0x2>;
		power_id = <0xffff>;
		power_vol = <0x0>;
		is_batch_supported = <0x0>;
	};
	cust_mag@1 {
		compatible = "mediatek,akm09911";
		i2c_num = <0x1>;
		i2c_addr = <0xc 0x0 0x0 0x0>;
		direction = <0x1>;
		power_id = <0xffff>;
		power_vol = <0x0>;
		is_batch_supported = <0x0>;
	};
	cust_mag@2 {
		compatible = "mediatek,st480";
		i2c_num = <0x1>;
		i2c_addr = <0xd 0x0 0x0 0x0>;
		direction = <0x1>;
		power_id = <0xffff>;
		power_vol = <0x0>;
		is_batch_supported = <0x0>;
	};
	cust_gyro@0 {
		compatible = "mediatek,bmi160_gyro";
		i2c_num = <0x1>;
		i2c_addr = <0x68 0x0 0x0 0x0>;
		direction = <0x1>;
		power_id = <0xffff>;
		power_vol = <0x0>;
		firlen = <0x0>;
		is_batch_supported = <0x0>;
	};
	cust_gyro@1 {
		compatible = "mediatek,lsm6ds3_gyro";
		i2c_num = <0x1>;
		i2c_addr = <0x6a 0x0 0x0 0x0>;
		direction = <0x2>;
		power_id = <0xffff>;
		power_vol = <0x0>;
		firlen = <0x0>;
		is_batch_supported = <0x0>;
	};
	cust_baro@0 {
		compatible = "mediatek,bmp280";
		i2c_num = <0x1>;
		i2c_addr = <0x77 0x0 0x0 0x0>;
		direction = <0x0>;
		power_id = <0xffff>;
		power_vol = <0x0>;
		firlen = <0x0>;
		is_batch_supported = <0x0>;
	};
	cust_hmdy@0 {
		compatible = "mediatek,hts221";
		i2c_num = <0x1>;
		i2c_addr = <0x5f 0x0 0x0 0x0>;
		direction = <0x0>;
		power_id = <0xffff>;
		power_vol = <0x0>;
		firlen = <0x0>;
		is_batch_supported = <0x0>;
	};
};
